AUTOSAR XML (schema 4-2-2)
package /STELLANTIS/EPT/ASWCs
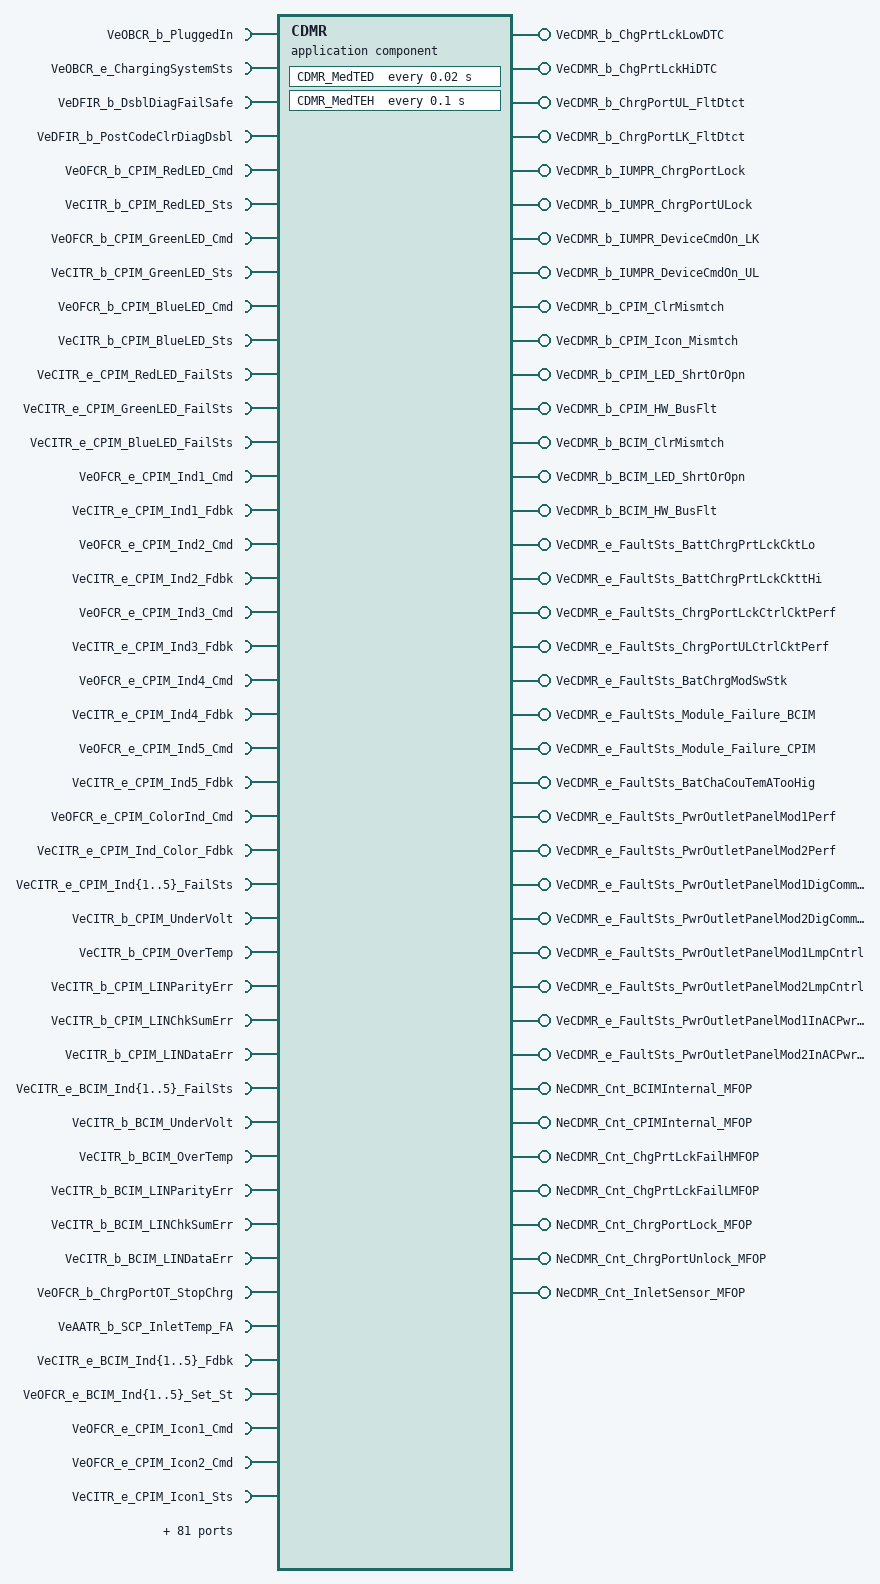
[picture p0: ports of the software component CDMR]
  application sw component type CDMR
    128 x require port:
      VeOBCR_b_PluggedIn: variation-point={short-label=vpVeOBCR_b_PluggedIn, sw-syscond=1}, nonqueued-receiver-com-spec{data-element=Value, init-value=0}, required-interface=VeOBCR_b_PluggedIn
      VeOBCR_e_ChargingSystemSts: variation-point={short-label=vpVeOBCR_e_ChargingSystemSts, sw-syscond=1}, nonqueued-receiver-com-spec{data-element=Value, init-value=CeOBCR_e_NotCharging}, required-interface=VeOBCR_e_ChargingSystemSts
      VeDFIR_b_DsblDiagFailSafe: variation-point={short-label=vpVeDFIR_b_DsblDiagFailSafe, sw-syscond=1}, nonqueued-receiver-com-spec{data-element=Value, init-value=0}, required-interface=VeDFIR_b_DsblDiagFailSafe
      VeDFIR_b_PostCodeClrDiagDsbl: variation-point={short-label=vpVeDFIR_b_PostCodeClrDiagDsbl, sw-syscond=1}, nonqueued-receiver-com-spec{data-element=Value, init-value=0}, required-interface=VeDFIR_b_PostCodeClrDiagDsbl
      VeOFCR_b_CPIM_RedLED_Cmd: variation-point={short-label=vpVeOFCR_b_CPIM_RedLED_Cmd, sw-syscond=1}, nonqueued-receiver-com-spec{data-element=Value, init-value=0}, required-interface=VeOFCR_b_CPIM_RedLED_Cmd
      VeCITR_b_CPIM_RedLED_Sts: variation-point={short-label=vpVeCITR_b_CPIM_RedLED_Sts, sw-syscond=1}, nonqueued-receiver-com-spec{data-element=Value, init-value=0}, required-interface=VeCITR_b_CPIM_RedLED_Sts
      VeOFCR_b_CPIM_GreenLED_Cmd: variation-point={short-label=vpVeOFCR_b_CPIM_GreenLED_Cmd, sw-syscond=1}, nonqueued-receiver-com-spec{data-element=Value, init-value=0}, required-interface=VeOFCR_b_CPIM_GreenLED_Cmd
      VeCITR_b_CPIM_GreenLED_Sts: variation-point={short-label=vpVeCITR_b_CPIM_GreenLED_Sts, sw-syscond=1}, nonqueued-receiver-com-spec{data-element=Value, init-value=0}, required-interface=VeCITR_b_CPIM_GreenLED_Sts
      VeOFCR_b_CPIM_BlueLED_Cmd: variation-point={short-label=vpVeOFCR_b_CPIM_BlueLED_Cmd, sw-syscond=1}, nonqueued-receiver-com-spec{data-element=Value, init-value=0}, required-interface=VeOFCR_b_CPIM_BlueLED_Cmd
      VeCITR_b_CPIM_BlueLED_Sts: variation-point={short-label=vpVeCITR_b_CPIM_BlueLED_Sts, sw-syscond=1}, nonqueued-receiver-com-spec{data-element=Value, init-value=0}, required-interface=VeCITR_b_CPIM_BlueLED_Sts
      VeCITR_e_CPIM_RedLED_FailSts: variation-point={short-label=vpVeCITR_e_CPIM_RedLED_FailSts, sw-syscond=1}, nonqueued-receiver-com-spec{data-element=Value, init-value=CeCITR_e_CPIM_LEDNormal}, required-interface=VeCITR_e_CPIM_RedLED_FailSts
      VeCITR_e_CPIM_GreenLED_FailSts: variation-point={short-label=vpVeCITR_e_CPIM_GreenLED_FailSts, sw-syscond=1}, nonqueued-receiver-com-spec{data-element=Value, init-value=CeCITR_e_CPIM_LEDNormal}, required-interface=VeCITR_e_CPIM_GreenLED_FailSts
      VeCITR_e_CPIM_BlueLED_FailSts: variation-point={short-label=vpVeCITR_e_CPIM_BlueLED_FailSts, sw-syscond=1}, nonqueued-receiver-com-spec{data-element=Value, init-value=CeCITR_e_CPIM_LEDNormal}, required-interface=VeCITR_e_CPIM_BlueLED_FailSts
      VeOFCR_e_CPIM_Ind1_Cmd: variation-point={short-label=vpVeOFCR_e_CPIM_Ind1_Cmd, sw-syscond=1}, nonqueued-receiver-com-spec{data-element=Value, init-value=CeCITR_e_CPIM_Ind_Off}, required-interface=VeOFCR_e_CPIM_Ind1_Cmd
      VeCITR_e_CPIM_Ind1_Fdbk: variation-point={short-label=vpVeCITR_e_CPIM_Ind1_Fdbk, sw-syscond=1}, nonqueued-receiver-com-spec{data-element=Value, init-value=CeCITR_e_CPIM_Ind_Off}, required-interface=VeCITR_e_CPIM_Ind1_Fdbk
      VeOFCR_e_CPIM_Ind2_Cmd: variation-point={short-label=vpVeOFCR_e_CPIM_Ind2_Cmd, sw-syscond=1}, nonqueued-receiver-com-spec{data-element=Value, init-value=CeCITR_e_CPIM_Ind_Off}, required-interface=VeOFCR_e_CPIM_Ind2_Cmd
      VeCITR_e_CPIM_Ind2_Fdbk: variation-point={short-label=vpVeCITR_e_CPIM_Ind2_Fdbk, sw-syscond=1}, nonqueued-receiver-com-spec{data-element=Value, init-value=CeCITR_e_CPIM_Ind_Off}, required-interface=VeCITR_e_CPIM_Ind2_Fdbk
      VeOFCR_e_CPIM_Ind3_Cmd: variation-point={short-label=vpVeOFCR_e_CPIM_Ind3_Cmd, sw-syscond=1}, nonqueued-receiver-com-spec{data-element=Value, init-value=CeCITR_e_CPIM_Ind_Off}, required-interface=VeOFCR_e_CPIM_Ind3_Cmd
      VeCITR_e_CPIM_Ind3_Fdbk: variation-point={short-label=vpVeCITR_e_CPIM_Ind3_Fdbk, sw-syscond=1}, nonqueued-receiver-com-spec{data-element=Value, init-value=CeCITR_e_CPIM_Ind_Off}, required-interface=VeCITR_e_CPIM_Ind3_Fdbk
      VeOFCR_e_CPIM_Ind4_Cmd: variation-point={short-label=vpVeOFCR_e_CPIM_Ind4_Cmd, sw-syscond=1}, nonqueued-receiver-com-spec{data-element=Value, init-value=CeCITR_e_CPIM_Ind_Off}, required-interface=VeOFCR_e_CPIM_Ind4_Cmd
      VeCITR_e_CPIM_Ind4_Fdbk: variation-point={short-label=vpVeCITR_e_CPIM_Ind4_Fdbk, sw-syscond=1}, nonqueued-receiver-com-spec{data-element=Value, init-value=CeCITR_e_CPIM_Ind_Off}, required-interface=VeCITR_e_CPIM_Ind4_Fdbk
      VeOFCR_e_CPIM_Ind5_Cmd: variation-point={short-label=vpVeOFCR_e_CPIM_Ind5_Cmd, sw-syscond=1}, nonqueued-receiver-com-spec{data-element=Value, init-value=CeCITR_e_CPIM_Ind_Off}, required-interface=VeOFCR_e_CPIM_Ind5_Cmd
      VeCITR_e_CPIM_Ind5_Fdbk: variation-point={short-label=vpVeCITR_e_CPIM_Ind5_Fdbk, sw-syscond=1}, nonqueued-receiver-com-spec{data-element=Value, init-value=CeCITR_e_CPIM_Ind_Off}, required-interface=VeCITR_e_CPIM_Ind5_Fdbk
      VeOFCR_e_CPIM_ColorInd_Cmd: variation-point={short-label=vpVeOFCR_e_CPIM_ColorInd_Cmd, sw-syscond=1}, nonqueued-receiver-com-spec{data-element=Value, init-value=CeCITR_e_CPIM_NoColor}, required-interface=VeOFCR_e_CPIM_ColorInd_Cmd
      VeCITR_e_CPIM_Ind_Color_Fdbk: variation-point={short-label=vpVeCITR_e_CPIM_Ind_Color_Fdbk, sw-syscond=1}, nonqueued-receiver-com-spec{data-element=Value, init-value=CeCITR_e_CPIM_NoColor}, required-interface=VeCITR_e_CPIM_Ind_Color_Fdbk
      VeCITR_e_CPIM_Ind{1..5}_FailSts: variation-point={short-label=vpVeCITR_e_CPIM_Ind{1..5}_FailSts, sw-syscond=1}, nonqueued-receiver-com-spec{data-element=Value, init-value=CeCITR_e_CPIM_LEDNormal}, required-interface=VeCITR_e_CPIM_Ind{1..5}_FailSts
      VeCITR_b_CPIM_UnderVolt: variation-point={short-label=vpVeCITR_b_CPIM_UnderVolt, sw-syscond=1}, nonqueued-receiver-com-spec{data-element=Value, init-value=0}, required-interface=VeCITR_b_CPIM_UnderVolt
      VeCITR_b_CPIM_OverTemp: variation-point={short-label=vpVeCITR_b_CPIM_OverTemp, sw-syscond=1}, nonqueued-receiver-com-spec{data-element=Value, init-value=0}, required-interface=VeCITR_b_CPIM_OverTemp
      VeCITR_b_CPIM_LINParityErr: variation-point={short-label=vpVeCITR_b_CPIM_LINParityErr, sw-syscond=1}, nonqueued-receiver-com-spec{data-element=Value, init-value=0}, required-interface=VeCITR_b_CPIM_LINParityErr
      VeCITR_b_CPIM_LINChkSumErr: variation-point={short-label=vpVeCITR_b_CPIM_LINChkSumErr, sw-syscond=1}, nonqueued-receiver-com-spec{data-element=Value, init-value=0}, required-interface=VeCITR_b_CPIM_LINChkSumErr
      VeCITR_b_CPIM_LINDataErr: variation-point={short-label=vpVeCITR_b_CPIM_LINDataErr, sw-syscond=1}, nonqueued-receiver-com-spec{data-element=Value, init-value=0}, required-interface=VeCITR_b_CPIM_LINDataErr
      VeCITR_e_BCIM_Ind{1..5}_FailSts: variation-point={short-label=vpVeCITR_e_BCIM_Ind{1..5}_FailSts, sw-syscond=1}, nonqueued-receiver-com-spec{data-element=Value, init-value=CeCITR_e_BCIM_LEDNormal}, required-interface=VeCITR_e_BCIM_Ind{1..5}_FailSts
      VeCITR_b_BCIM_UnderVolt: variation-point={short-label=vpVeCITR_b_BCIM_UnderVolt, sw-syscond=1}, nonqueued-receiver-com-spec{data-element=Value, init-value=0}, required-interface=VeCITR_b_BCIM_UnderVolt
      VeCITR_b_BCIM_OverTemp: variation-point={short-label=vpVeCITR_b_BCIM_OverTemp, sw-syscond=1}, nonqueued-receiver-com-spec{data-element=Value, init-value=0}, required-interface=VeCITR_b_BCIM_OverTemp
      VeCITR_b_BCIM_LINParityErr: variation-point={short-label=vpVeCITR_b_BCIM_LINParityErr, sw-syscond=1}, nonqueued-receiver-com-spec{data-element=Value, init-value=0}, required-interface=VeCITR_b_BCIM_LINParityErr
      VeCITR_b_BCIM_LINChkSumErr: variation-point={short-label=vpVeCITR_b_BCIM_LINChkSumErr, sw-syscond=1}, nonqueued-receiver-com-spec{data-element=Value, init-value=0}, required-interface=VeCITR_b_BCIM_LINChkSumErr
      VeCITR_b_BCIM_LINDataErr: variation-point={short-label=vpVeCITR_b_BCIM_LINDataErr, sw-syscond=1}, nonqueued-receiver-com-spec{data-element=Value, init-value=0}, required-interface=VeCITR_b_BCIM_LINDataErr
      VeOFCR_b_ChrgPortOT_StopChrg: variation-point={short-label=vpVeOFCR_b_ChrgPortOT_StopChrg, sw-syscond=1}, nonqueued-receiver-com-spec{data-element=Value, init-value=0}, required-interface=VeOFCR_b_ChrgPortOT_StopChrg
      VeAATR_b_SCP_InletTemp_FA: variation-point={short-label=vpVeAATR_b_SCP_InletTemp_FA, sw-syscond=1}, nonqueued-receiver-com-spec{data-element=Value, init-value=0}, required-interface=VeAATR_b_SCP_InletTemp_FA
      VeCITR_e_BCIM_Ind{1..5}_Fdbk: variation-point={short-label=vpVeCITR_e_BCIM_Ind{1..5}_Fdbk, sw-syscond=1}, nonqueued-receiver-com-spec{data-element=Value, init-value=CeCITR_e_BCIM_Ind_Off}, required-interface=VeCITR_e_BCIM_Ind{1..5}_Fdbk
      VeOFCR_e_BCIM_Ind{1..5}_Set_St: variation-point={short-label=vpVeOFCR_e_BCIM_Ind{1..5}_Set_St, sw-syscond=1}, nonqueued-receiver-com-spec{data-element=Value, init-value=CeCITR_e_BCIM_Ind_Off}, required-interface=VeOFCR_e_BCIM_Ind{1..5}_Set_St
      VeOFCR_e_CPIM_Icon1_Cmd: variation-point={short-label=vpVeOFCR_e_CPIM_Icon1_Cmd, sw-syscond=1}, nonqueued-receiver-com-spec{data-element=Value, init-value=CeCITR_e_CPIM_Icon_OFF}, required-interface=VeOFCR_e_CPIM_Icon1_Cmd
      VeOFCR_e_CPIM_Icon2_Cmd: variation-point={short-label=vpVeOFCR_e_CPIM_Icon2_Cmd, sw-syscond=1}, nonqueued-receiver-com-spec{data-element=Value, init-value=CeCITR_e_CPIM_Icon_OFF}, required-interface=VeOFCR_e_CPIM_Icon2_Cmd
      VeCITR_e_CPIM_Icon1_Sts: variation-point={short-label=vpVeCITR_e_CPIM_Icon1_Sts, sw-syscond=1}, nonqueued-receiver-com-spec{data-element=Value, init-value=CeCITR_e_CPIM_Icon_OFF}, required-interface=VeCITR_e_CPIM_Icon1_Sts
      VeCITR_e_CPIM_Icon2_Sts: variation-point={short-label=vpVeCITR_e_CPIM_Icon2_Sts, sw-syscond=1}, nonqueued-receiver-com-spec{data-element=Value, init-value=CeCITR_e_CPIM_Icon_OFF}, required-interface=VeCITR_e_CPIM_Icon2_Sts
      VeOBCR_b_ChrgSysFault: variation-point={short-label=vpVeOBCR_b_ChrgSysFault, sw-syscond=1}, nonqueued-receiver-com-spec{data-element=Value, init-value=0}, required-interface=VeOBCR_b_ChrgSysFault
      VeCITR_b_ChrgPortButton_Sts: variation-point={short-label=vpVeCITR_b_ChrgPortButton_Sts, sw-syscond=1}, nonqueued-receiver-com-spec{data-element=Value, init-value=0}, required-interface=VeCITR_b_ChrgPortButton_Sts
      VeSCPR_b_ButtonActive_Door: variation-point={short-label=vpVeSCPR_b_ButtonActive_Door, sw-syscond=1}, nonqueued-receiver-com-spec{data-element=Value, init-value=0}, required-interface=VeSCPR_b_ButtonActive_Door
      VeOBCR_e_ChrgPort_Req: variation-point={short-label=vpVeOBCR_e_ChrgPort_Req, sw-syscond=1}, nonqueued-receiver-com-spec{data-element=Value, init-value=CeOBCR_e_PortNoRequest}, required-interface=VeOBCR_e_ChrgPort_Req
      VeCITR_b_PortLockBCM_Cmd: variation-point={short-label=vpVeCITR_b_PortLockBCM_Cmd, sw-syscond=1}, nonqueued-receiver-com-spec{data-element=Value, init-value=0}, required-interface=VeCITR_b_PortLockBCM_Cmd
      VeCITR_b_ChrgPortLockSts: variation-point={short-label=vpVeCITR_b_ChrgPortLockSts, sw-syscond=1}, nonqueued-receiver-com-spec{data-element=Value, init-value=0}, required-interface=VeCITR_b_ChrgPortLockSts
      VeCANR_b_CBCLossComm_InKeyOff: variation-point={short-label=vpVeCANR_b_CBCLossComm_InKeyOff, sw-syscond=1}, nonqueued-receiver-com-spec{data-element=VeCANR_b_CBCLossComm_InKeyOff, init-value=0}, required-interface=VeCANR_b_CBCLossComm_InKeyOff
      VeCITR_e_ChrgPortLock_StsB: variation-point={short-label=vpVeCITR_e_ChrgPortLock_StsB, sw-syscond=1}, nonqueued-receiver-com-spec{data-element=Value, init-value=CeOBCR_e_DefaultLock_Sts}, required-interface=VeCITR_e_ChrgPortLock_StsB
      VeCITR_b_ChrgPortLock_StsB_FA: variation-point={short-label=vpVeCITR_b_ChrgPortLock_StsB_FA, sw-syscond=1}, nonqueued-receiver-com-spec{data-element=Value, init-value=0}, required-interface=VeCITR_b_ChrgPortLock_StsB_FA
      VeCITR_b_ChrgPortLock_StsC: variation-point={short-label=vpVeCITR_b_ChrgPortLock_StsC, sw-syscond=1}, nonqueued-receiver-com-spec{data-element=Value, init-value=0}, required-interface=VeCITR_b_ChrgPortLock_StsC
      VeCITR_b_ChrgPortLock_StsC_FA: variation-point={short-label=vpVeCITR_b_ChrgPortLock_StsC_FA, sw-syscond=1}, nonqueued-receiver-com-spec{data-element=Value, init-value=0}, required-interface=VeCITR_b_ChrgPortLock_StsC_FA
      VeCITR_b_HBridge_ChrgPortLck_Cal: variation-point={short-label=vpVeCITR_b_HBridge_ChrgPortLck_Cal, sw-syscond=1}, nonqueued-receiver-com-spec{data-element=Value, init-value=0}, required-interface=VeCITR_b_HBridge_ChrgPortLck_Cal
      VeCITR_d_ChrgPortHbridgeFlt: variation-point={short-label=vpVeCITR_d_ChrgPortHbridgeFlt, sw-syscond=1}, nonqueued-receiver-com-spec{data-element=Value, init-value=0}, required-interface=VeCITR_d_ChrgPortHbridgeFlt
      VeCITR_e_CPIM_ChrgPortLock_FailSts: variation-point={short-label=vpVeCITR_e_CPIM_ChrgPortLock_FailSts, sw-syscond=1}, nonqueued-receiver-com-spec{data-element=Value, init-value=CeCITR_e_CPIMLock_Nofailure}, required-interface=VeCITR_e_CPIM_ChrgPortLock_FailSts
      VeDFIR_b_IsDiagGlobalConditionsValid: variation-point={short-label=vpVeDFIR_b_IsDiagGlobalConditionsValid, sw-syscond=1}, nonqueued-receiver-com-spec{data-element=Value, init-value=0}, required-interface=VeDFIR_b_IsDiagGlobalConditionsValid
      VeOFCR_e_BCIM_ColorInd_Cmd: variation-point={short-label=vpVeOFCR_e_BCIM_ColorInd_Cmd, sw-syscond=1}, nonqueued-receiver-com-spec{data-element=Value, init-value=CeCITR_e_BCIM_NoColor}, required-interface=VeOFCR_e_BCIM_ColorInd_Cmd
      VeCITR_e_BCIM_Ind_Color_Fdbk: variation-point={short-label=vpVeCITR_e_BCIM_Ind_Color_Fdbk, sw-syscond=1}, nonqueued-receiver-com-spec{data-element=Value, init-value=CeCITR_e_BCIM_NoColor}, required-interface=VeCITR_e_BCIM_Ind_Color_Fdbk
      VeCITR_b_CPIM_Icon1_FailSts: variation-point={short-label=vpVeCITR_b_CPIM_Icon1_FailSts, sw-syscond=1}, nonqueued-receiver-com-spec{data-element=Value, init-value=0}, required-interface=VeCITR_b_CPIM_Icon1_FailSts
      VeCITR_b_CPIM_Icon2_FailSts: variation-point={short-label=vpVeCITR_b_CPIM_Icon2_FailSts, sw-syscond=1}, nonqueued-receiver-com-spec{data-element=Value, init-value=0}, required-interface=VeCITR_b_CPIM_Icon2_FailSts
      VeDMAB_y_StatusByte_HiSpdCANCommBus: variation-point={short-label=vpVeDMAB_y_StatusByte_HiSpdCANCommBus, sw-syscond=1}, nonqueued-receiver-com-spec{data-element=Value, init-value=0}, required-interface=VeDMAB_y_StatusByte_HiSpdCANCommBus
      VeDMAB_y_StatusByte_LostCommBCM: variation-point={short-label=vpVeDMAB_y_StatusByte_LostCommBCM, sw-syscond=1}, nonqueued-receiver-com-spec{data-element=Value, init-value=0}, required-interface=VeDMAB_y_StatusByte_LostCommBCM
      VeDMAB_y_StatusByte_LIN{1..3}_BusOff: variation-point={short-label=vpVeDMAB_y_StatusByte_LIN{1..3}_BusOff, sw-syscond=1}, nonqueued-receiver-com-spec{data-element=Value, init-value=0}, required-interface=VeDMAB_y_StatusByte_LIN{1..3}_BusOff
      VeDMAB_y_StatusByte_LostCommCPIM: variation-point={short-label=vpVeDMAB_y_StatusByte_LostCommCPIM, sw-syscond=1}, nonqueued-receiver-com-spec{data-element=Value, init-value=0}, required-interface=VeDMAB_y_StatusByte_LostCommCPIM
      VeDMAB_y_StatusByte_LostCommBCIM: variation-point={short-label=vpVeDMAB_y_StatusByte_LostCommBCIM, sw-syscond=1}, nonqueued-receiver-com-spec{data-element=Value, init-value=0}, required-interface=VeDMAB_y_StatusByte_LostCommBCIM
      VeDMAB_y_StatusByte_BatChrgModSwStk: variation-point={short-label=vpVeDMAB_y_StatusByte_BatChrgModSwStk, sw-syscond=1}, nonqueued-receiver-com-spec{data-element=Value, init-value=0}, required-interface=VeDMAB_y_StatusByte_BatChrgModSwStk
      VeDMAB_y_StatusByte_Module_Failure_CPIM: variation-point={short-label=vpVeDMAB_y_StatusByte_Module_Failure_CPIM, sw-syscond=1}, nonqueued-receiver-com-spec{data-element=Value, init-value=0}, required-interface=VeDMAB_y_StatusByte_Module_Failure_CPIM
      VeDMAB_y_StatusByte_Module_Failure_BCIM: variation-point={short-label=vpVeDMAB_y_StatusByte_Module_Failure_BCIM, sw-syscond=1}, nonqueued-receiver-com-spec{data-element=Value, init-value=0}, required-interface=VeDMAB_y_StatusByte_Module_Failure_BCIM
      VeDMAB_y_StatusByte_BatChaCouTemATooHig: variation-point={short-label=vpVeDMAB_y_StatusByte_BatChaCouTemATooHig, sw-syscond=1}, nonqueued-receiver-com-spec{data-element=Value, init-value=0}, required-interface=VeDMAB_y_StatusByte_BatChaCouTemATooHig
      VeDMAB_y_StatusByte_ChrgPortLckCtrlCktPerf: variation-point={short-label=vpVeDMAB_y_StatusByte_ChrgPortLckCtrlCktPerf, sw-syscond=1}, nonqueued-receiver-com-spec{data-element=Value, init-value=0}, required-interface=VeDMAB_y_StatusByte_ChrgPortLckCtrlCktPerf
      VeDMAB_y_StatusByte_ChrgPortULCtrlCktPerf: variation-point={short-label=vpVeDMAB_y_StatusByte_ChrgPortULCtrlCktPerf, sw-syscond=1}, nonqueued-receiver-com-spec{data-element=Value, init-value=0}, required-interface=VeDMAB_y_StatusByte_ChrgPortULCtrlCktPerf
      VeDMAB_y_StatusByte_BattChrgPrtLckCkttHi: variation-point={short-label=vpVeDMAB_y_StatusByte_BattChrgPrtLckCkttHi, sw-syscond=1}, nonqueued-receiver-com-spec{data-element=Value, init-value=0}, required-interface=VeDMAB_y_StatusByte_BattChrgPrtLckCkttHi
      VeDMAB_y_StatusByte_BattChrgPrtLckCktLo: variation-point={short-label=vpVeDMAB_y_StatusByte_BattChrgPrtLckCktLo, sw-syscond=1}, nonqueued-receiver-com-spec{data-element=Value, init-value=0}, required-interface=VeDMAB_y_StatusByte_BattChrgPrtLckCktLo
      VeVTLR_e_TrunkSts: variation-point={short-label=vpVeVTLR_e_TrunkSts, sw-syscond=1}, nonqueued-receiver-com-spec{data-element=Value, init-value=CeVTLR_e_Inactive}, required-interface=VeVTLR_e_TrunkSts
      VeDMAB_y_StatusByte_PwrOutletPanelMod1Perf: variation-point={short-label=vpVeDMAB_y_StatusByte_PwrOutletPanelMod1Perf, sw-syscond=1}, nonqueued-receiver-com-spec{data-element=Value, init-value=0}, required-interface=VeDMAB_y_StatusByte_PwrOutletPanelMod1Perf
      VeCITR_b_PP2ButtonSts: variation-point={short-label=vpVeCITR_b_PP2ButtonSts, sw-syscond=1}, nonqueued-receiver-com-spec{data-element=Value, init-value=0}, required-interface=VeCITR_b_PP2ButtonSts
      VePMDB_b_PwrPanSwStatus: variation-point={short-label=vpVePMDB_b_PwrPanSwStatus, sw-syscond=1}, nonqueued-receiver-com-spec{data-element=Value, init-value=0}, required-interface=VePMDB_b_PwrPanSwStatus
      VeDMAB_y_StatusByte_PwrOutletPanelMod1DigCommBus: variation-point={short-label=vpVeDMAB_y_StatusByte_PwrOutletPanelMod1DigCommBus, sw-syscond=1}, nonqueued-receiver-com-spec{data-element=Value, init-value=0}, required-interface=VeDMAB_y_StatusByte_PwrOutletPanelMod1DigCommBus
      VePMTR_e_ThrmlDevEnbl: variation-point={short-label=vpVePMTR_e_ThrmlDevEnbl, sw-syscond=1}, nonqueued-receiver-com-spec{data-element=Value, init-value=CePMTR_e_DISBL_All_Thrml}, required-interface=VePMTR_e_ThrmlDevEnbl
      VeCITR_e_PP_LED_A_Feedback: variation-point={short-label=vpVeCITR_e_PP_LED_A_Feedback, sw-syscond=1}, nonqueued-receiver-com-spec{data-element=Value, init-value=CeCITR_e_CPIM_Ind_Off}, required-interface=VeCITR_e_PP_LED_A_Feedback
      VeCITR_e_PP_LED_B_Feedback: variation-point={short-label=vpVeCITR_e_PP_LED_B_Feedback, sw-syscond=1}, nonqueued-receiver-com-spec{data-element=Value, init-value=CeCITR_e_CPIM_Ind_Off}, required-interface=VeCITR_e_PP_LED_B_Feedback
      VeCITR_e_PP_LED_A_FailStatus: variation-point={short-label=vpVeCITR_e_PP_LED_A_FailStatus, sw-syscond=1}, nonqueued-receiver-com-spec{data-element=Value, init-value=CeCITR_e_CPIM_LEDNormal}, required-interface=VeCITR_e_PP_LED_A_FailStatus
      VeCITR_e_PP_LED_B_FailStatus: variation-point={short-label=vpVeCITR_e_PP_LED_B_FailStatus, sw-syscond=1}, nonqueued-receiver-com-spec{data-element=Value, init-value=CeCITR_e_CPIM_LEDNormal}, required-interface=VeCITR_e_PP_LED_B_FailStatus
      VeVTLR_e_PP1_LEDA_Cmd: variation-point={short-label=vpVeVTLR_e_PP1_LEDA_Cmd, sw-syscond=1}, nonqueued-receiver-com-spec{data-element=Value, init-value=CeVTLR_e_Led_Off}, required-interface=VeVTLR_e_PP1_LEDA_Cmd
      VeVTLR_e_PP1_LEDB_Cmd: variation-point={short-label=vpVeVTLR_e_PP1_LEDB_Cmd, sw-syscond=1}, nonqueued-receiver-com-spec{data-element=Value, init-value=CeVTLR_e_Led_Off}, required-interface=VeVTLR_e_PP1_LEDB_Cmd
      VeDMAB_y_StatusByte_PwrOutletPanelMod1LmpCntrl: variation-point={short-label=vpVeDMAB_y_StatusByte_PwrOutletPanelMod1LmpCntrl, sw-syscond=1}, nonqueued-receiver-com-spec{data-element=Value, init-value=0}, required-interface=VeDMAB_y_StatusByte_PwrOutletPanelMod1LmpCntrl
      VeIDCR_U_ACOutVoltage1: variation-point={short-label=vpVeIDCR_U_ACOutVoltage1, sw-syscond=1}, nonqueued-receiver-com-spec{data-element=Value, init-value=0}, required-interface=VeIDCR_U_ACOutVoltage1
      VeCITR_b_PPACPresentSens1: variation-point={short-label=vpVeCITR_b_PPACPresentSens1, sw-syscond=1}, nonqueued-receiver-com-spec{data-element=Value, init-value=0}, required-interface=VeCITR_b_PPACPresentSens1
      VeDMAB_y_StatusByte_PwrOutletPanelMod1InACPwrCktPerf: variation-point={short-label=vpVeDMAB_y_StatusByte_PwrOutletPanelMod1InACPwrCktPerf, sw-syscond=1}, nonqueued-receiver-com-spec{data-element=Value, init-value=0}, required-interface=VeDMAB_y_StatusByte_PwrOutletPanelMod1InACPwrCktPerf
      VeDMAB_y_StatusByte_PwrOutletPanelMod2Perf: variation-point={short-label=vpVeDMAB_y_StatusByte_PwrOutletPanelMod2Perf, sw-syscond=1}, nonqueued-receiver-com-spec{data-element=Value, init-value=0}, required-interface=VeDMAB_y_StatusByte_PwrOutletPanelMod2Perf
      VeCITR_b_PPButtonSts: variation-point={short-label=vpVeCITR_b_PPButtonSts, sw-syscond=1}, nonqueued-receiver-com-spec{data-element=Value, init-value=0}, required-interface=VeCITR_b_PPButtonSts
      VeDMAB_y_StatusByte_PwrOutletPanelMod2DigCommBus: variation-point={short-label=vpVeDMAB_y_StatusByte_PwrOutletPanelMod2DigCommBus, sw-syscond=1}, nonqueued-receiver-com-spec{data-element=Value, init-value=0}, required-interface=VeDMAB_y_StatusByte_PwrOutletPanelMod2DigCommBus
      VeCITR_e_PP2_LED_A_Feedback: variation-point={short-label=vpVeCITR_e_PP2_LED_A_Feedback, sw-syscond=1}, nonqueued-receiver-com-spec{data-element=Value, init-value=CeCITR_e_CPIM_Ind_Off}, required-interface=VeCITR_e_PP2_LED_A_Feedback
      VeCITR_e_PP2_LED_B_Feedback: variation-point={short-label=vpVeCITR_e_PP2_LED_B_Feedback, sw-syscond=1}, nonqueued-receiver-com-spec{data-element=Value, init-value=CeCITR_e_CPIM_Ind_Off}, required-interface=VeCITR_e_PP2_LED_B_Feedback
      VeCITR_e_PP2_LED_A_FailStatus: variation-point={short-label=vpVeCITR_e_PP2_LED_A_FailStatus, sw-syscond=1}, nonqueued-receiver-com-spec{data-element=Value, init-value=CeCITR_e_CPIM_LEDNormal}, required-interface=VeCITR_e_PP2_LED_A_FailStatus
      VeCITR_e_PP2_LED_B_FailStatus: variation-point={short-label=vpVeCITR_e_PP2_LED_B_FailStatus, sw-syscond=1}, nonqueued-receiver-com-spec{data-element=Value, init-value=CeCITR_e_CPIM_LEDNormal}, required-interface=VeCITR_e_PP2_LED_B_FailStatus
      VeVTLR_e_PP2_LEDA_Cmd: variation-point={short-label=vpVeVTLR_e_PP2_LEDA_Cmd, sw-syscond=1}, nonqueued-receiver-com-spec{data-element=Value, init-value=CeVTLR_e_Led_Off}, required-interface=VeVTLR_e_PP2_LEDA_Cmd
      VeVTLR_e_PP2_LEDB_Cmd: variation-point={short-label=vpVeVTLR_e_PP2_LEDB_Cmd, sw-syscond=1}, nonqueued-receiver-com-spec{data-element=Value, init-value=CeVTLR_e_Led_Off}, required-interface=VeVTLR_e_PP2_LEDB_Cmd
      VeDMAB_y_StatusByte_PwrOutletPanelMod2LmpCntrl: variation-point={short-label=vpVeDMAB_y_StatusByte_PwrOutletPanelMod2LmpCntrl, sw-syscond=1}, nonqueued-receiver-com-spec{data-element=Value, init-value=0}, required-interface=VeDMAB_y_StatusByte_PwrOutletPanelMod2LmpCntrl
      VeCITR_b_PP2ACPresentSens1: variation-point={short-label=vpVeCITR_b_PP2ACPresentSens1, sw-syscond=1}, nonqueued-receiver-com-spec{data-element=Value, init-value=0}, required-interface=VeCITR_b_PP2ACPresentSens1
      VeDMAB_y_StatusByte_PwrOutletPanelMod2InACPwrCktPerf: variation-point={short-label=vpVeDMAB_y_StatusByte_PwrOutletPanelMod2InACPwrCktPerf, sw-syscond=1}, nonqueued-receiver-com-spec{data-element=Value, init-value=0}, required-interface=VeDMAB_y_StatusByte_PwrOutletPanelMod2InACPwrCktPerf
      VeCITR_I_PP2CurrentDrawSens1: variation-point={short-label=vpVeCITR_I_PP2CurrentDrawSens1, sw-syscond=1}, nonqueued-receiver-com-spec{data-element=Value, init-value=0}, required-interface=VeCITR_I_PP2CurrentDrawSens1
      VeVTLR_e_FrunkSts: variation-point={short-label=vpVeVTLR_e_FrunkSts, sw-syscond=1}, nonqueued-receiver-com-spec{data-element=Value, init-value=CeVTLR_e_Inactive_Frunk}, required-interface=VeVTLR_e_FrunkSts
      VeVTLR_b_ACSw_Cmd: variation-point={short-label=vpVeVTLR_b_ACSw_Cmd, sw-syscond=1}, nonqueued-receiver-com-spec{data-element=Value, init-value=0}, required-interface=VeVTLR_b_ACSw_Cmd
      VeCITR_I_PPCurrentDrawSens1: variation-point={short-label=vpVeCITR_I_PPCurrentDrawSens1, sw-syscond=1}, nonqueued-receiver-com-spec{data-element=Value, init-value=0}, required-interface=VeCITR_I_PPCurrentDrawSens1
      VeIDCR_I_ACOutCurrent1: variation-point={short-label=vpVeIDCR_I_ACOutCurrent1, sw-syscond=1}, nonqueued-receiver-com-spec{data-element=Value, init-value=0}, required-interface=VeIDCR_I_ACOutCurrent1
    31 x provide port:
      VeCDMR_b_ChgPrtLckLowDTC: nonqueued-sender-com-spec{data-element=Value, init-value=0}, provided-interface=VeCDMR_b_ChgPrtLckLowDTC
      VeCDMR_b_ChgPrtLckHiDTC: nonqueued-sender-com-spec{data-element=Value, init-value=0}, provided-interface=VeCDMR_b_ChgPrtLckHiDTC
      VeCDMR_b_ChrgPortUL_FltDtct: nonqueued-sender-com-spec{data-element=Value, init-value=0}, provided-interface=VeCDMR_b_ChrgPortUL_FltDtct
      VeCDMR_b_ChrgPortLK_FltDtct: nonqueued-sender-com-spec{data-element=Value, init-value=0}, provided-interface=VeCDMR_b_ChrgPortLK_FltDtct
      VeCDMR_b_IUMPR_ChrgPortLock: nonqueued-sender-com-spec{data-element=Value, init-value=0}, provided-interface=VeCDMR_b_IUMPR_ChrgPortLock
      VeCDMR_b_IUMPR_ChrgPortULock: nonqueued-sender-com-spec{data-element=Value, init-value=0}, provided-interface=VeCDMR_b_IUMPR_ChrgPortULock
      VeCDMR_b_IUMPR_DeviceCmdOn_LK: nonqueued-sender-com-spec{data-element=Value, init-value=0}, provided-interface=VeCDMR_b_IUMPR_DeviceCmdOn_LK
      VeCDMR_b_IUMPR_DeviceCmdOn_UL: nonqueued-sender-com-spec{data-element=Value, init-value=0}, provided-interface=VeCDMR_b_IUMPR_DeviceCmdOn_UL
      VeCDMR_b_CPIM_ClrMismtch: nonqueued-sender-com-spec{data-element=Value, init-value=0}, provided-interface=VeCDMR_b_CPIM_ClrMismtch
      VeCDMR_b_CPIM_Icon_Mismtch: nonqueued-sender-com-spec{data-element=Value, init-value=0}, provided-interface=VeCDMR_b_CPIM_Icon_Mismtch
      VeCDMR_b_CPIM_LED_ShrtOrOpn: nonqueued-sender-com-spec{data-element=Value, init-value=0}, provided-interface=VeCDMR_b_CPIM_LED_ShrtOrOpn
      VeCDMR_b_CPIM_HW_BusFlt: nonqueued-sender-com-spec{data-element=Value, init-value=0}, provided-interface=VeCDMR_b_CPIM_HW_BusFlt
      VeCDMR_b_BCIM_ClrMismtch: nonqueued-sender-com-spec{data-element=Value, init-value=0}, provided-interface=VeCDMR_b_BCIM_ClrMismtch
      VeCDMR_b_BCIM_LED_ShrtOrOpn: nonqueued-sender-com-spec{data-element=Value, init-value=0}, provided-interface=VeCDMR_b_BCIM_LED_ShrtOrOpn
      VeCDMR_b_BCIM_HW_BusFlt: nonqueued-sender-com-spec{data-element=Value, init-value=0}, provided-interface=VeCDMR_b_BCIM_HW_BusFlt
      VeCDMR_e_FaultSts_BattChrgPrtLckCktLo: nonqueued-sender-com-spec{data-element=Value, init-value=CeDFIB_e_Init}, provided-interface=VeCDMR_e_FaultSts_BattChrgPrtLckCktLo
      VeCDMR_e_FaultSts_BattChrgPrtLckCkttHi: nonqueued-sender-com-spec{data-element=Value, init-value=CeDFIB_e_Init}, provided-interface=VeCDMR_e_FaultSts_BattChrgPrtLckCkttHi
      VeCDMR_e_FaultSts_ChrgPortLckCtrlCktPerf: nonqueued-sender-com-spec{data-element=Value, init-value=CeDFIB_e_Init}, provided-interface=VeCDMR_e_FaultSts_ChrgPortLckCtrlCktPerf
      VeCDMR_e_FaultSts_ChrgPortULCtrlCktPerf: nonqueued-sender-com-spec{data-element=Value, init-value=CeDFIB_e_Init}, provided-interface=VeCDMR_e_FaultSts_ChrgPortULCtrlCktPerf
      VeCDMR_e_FaultSts_BatChrgModSwStk: nonqueued-sender-com-spec{data-element=Value, init-value=CeDFIB_e_Init}, provided-interface=VeCDMR_e_FaultSts_BatChrgModSwStk
      VeCDMR_e_FaultSts_Module_Failure_BCIM: nonqueued-sender-com-spec{data-element=Value, init-value=CeDFIB_e_Init}, provided-interface=VeCDMR_e_FaultSts_Module_Failure_BCIM
      VeCDMR_e_FaultSts_Module_Failure_CPIM: nonqueued-sender-com-spec{data-element=Value, init-value=CeDFIB_e_Init}, provided-interface=VeCDMR_e_FaultSts_Module_Failure_CPIM
      VeCDMR_e_FaultSts_BatChaCouTemATooHig: nonqueued-sender-com-spec{data-element=Value, init-value=CeDFIB_e_Init}, provided-interface=VeCDMR_e_FaultSts_BatChaCouTemATooHig
      VeCDMR_e_FaultSts_PwrOutletPanelMod1Perf: nonqueued-sender-com-spec{data-element=Value, init-value=CeDFIB_e_Init}, provided-interface=VeCDMR_e_FaultSts_PwrOutletPanelMod1Perf
      VeCDMR_e_FaultSts_PwrOutletPanelMod2Perf: nonqueued-sender-com-spec{data-element=Value, init-value=CeDFIB_e_Init}, provided-interface=VeCDMR_e_FaultSts_PwrOutletPanelMod2Perf
      VeCDMR_e_FaultSts_PwrOutletPanelMod1DigCommBus: nonqueued-sender-com-spec{data-element=Value, init-value=CeDFIB_e_Init}, provided-interface=VeCDMR_e_FaultSts_PwrOutletPanelMod1DigCommBus
      VeCDMR_e_FaultSts_PwrOutletPanelMod2DigCommBus: nonqueued-sender-com-spec{data-element=Value, init-value=CeDFIB_e_Init}, provided-interface=VeCDMR_e_FaultSts_PwrOutletPanelMod2DigCommBus
      VeCDMR_e_FaultSts_PwrOutletPanelMod1LmpCntrl: nonqueued-sender-com-spec{data-element=Value, init-value=CeDFIB_e_Init}, provided-interface=VeCDMR_e_FaultSts_PwrOutletPanelMod1LmpCntrl
      VeCDMR_e_FaultSts_PwrOutletPanelMod2LmpCntrl: nonqueued-sender-com-spec{data-element=Value, init-value=CeDFIB_e_Init}, provided-interface=VeCDMR_e_FaultSts_PwrOutletPanelMod2LmpCntrl
      VeCDMR_e_FaultSts_PwrOutletPanelMod1InACPwrCktPerf: nonqueued-sender-com-spec{data-element=Value, init-value=CeDFIB_e_Init}, provided-interface=VeCDMR_e_FaultSts_PwrOutletPanelMod1InACPwrCktPerf
      VeCDMR_e_FaultSts_PwrOutletPanelMod2InACPwrCktPerf: nonqueued-sender-com-spec{data-element=Value, init-value=CeDFIB_e_Init}, provided-interface=VeCDMR_e_FaultSts_PwrOutletPanelMod2InACPwrCktPerf
    15 x require port:
      NeCDMR_Cnt_BCIMInternal_MFOP_Rx: nv-require-com-spec{init-value=0, variable=NeCDMR_Cnt_BCIMInternal_MFOP}, required-interface=NeCDMR_Cnt_BCIMInternal_MFOP
      NeCDMR_Cnt_CPIMInternal_MFOP_Rx: nv-require-com-spec{init-value=0, variable=NeCDMR_Cnt_CPIMInternal_MFOP}, required-interface=NeCDMR_Cnt_CPIMInternal_MFOP
      NeCDMR_Cnt_ChgPrtLckFailHMFOP_Rx: nv-require-com-spec{init-value=0, variable=NeCDMR_Cnt_ChgPrtLckFailHMFOP}, required-interface=NeCDMR_Cnt_ChgPrtLckFailHMFOP
      NeCDMR_Cnt_ChgPrtLckFailLMFOP_Rx: nv-require-com-spec{init-value=0, variable=NeCDMR_Cnt_ChgPrtLckFailLMFOP}, required-interface=NeCDMR_Cnt_ChgPrtLckFailLMFOP
      NeCDMR_Cnt_ChrgPortLock_MFOP_Rx: nv-require-com-spec{init-value=0, variable=NeCDMR_Cnt_ChrgPortLock_MFOP}, required-interface=NeCDMR_Cnt_ChrgPortLock_MFOP
      NeCDMR_Cnt_ChrgPortUnlock_MFOP_Rx: nv-require-com-spec{init-value=0, variable=NeCDMR_Cnt_ChrgPortUnlock_MFOP}, required-interface=NeCDMR_Cnt_ChrgPortUnlock_MFOP
      NeCDMR_Cnt_InletSensor_MFOP_Rx: nv-require-com-spec{init-value=0, variable=NeCDMR_Cnt_InletSensor_MFOP}, required-interface=NeCDMR_Cnt_InletSensor_MFOP
      NeCDMR_Cnt_PwrOutletPanelMod1Perf_MFOP_Rx: nv-require-com-spec{init-value=0, variable=NeCDMR_Cnt_PwrOutletPanelMod1Perf_MFOP}, required-interface=NeCDMR_Cnt_PwrOutletPanelMod1Perf_MFOP
      NeCDMR_Cnt_DTCShortName6_MFOP_Rx: nv-require-com-spec{init-value=0, variable=NeCDMR_Cnt_DTCShortName6_MFOP}, required-interface=NeCDMR_Cnt_DTCShortName6_MFOP
      NeCDMR_Cnt_DTCShortName1_MFOP_Rx: nv-require-com-spec{init-value=0, variable=NeCDMR_Cnt_DTCShortName1_MFOP}, required-interface=NeCDMR_Cnt_DTCShortName1_MFOP
      NeCDMR_Cnt_PwrOutletPanelMod2DigCommBus_MFOP_Rx: nv-require-com-spec{init-value=0, variable=NeCDMR_Cnt_PwrOutletPanelMod2DigCommBus_MFOP}, required-interface=NeCDMR_Cnt_PwrOutletPanelMod2DigCommBus_MFOP
      NeCDMR_Cnt_PwrOutletPanelMod1LmpCntrl_MFOP_Rx: nv-require-com-spec{init-value=0, variable=NeCDMR_Cnt_PwrOutletPanelMod1LmpCntrl_MFOP}, required-interface=NeCDMR_Cnt_PwrOutletPanelMod1LmpCntrl_MFOP
      NeCDMR_Cnt_PwrOutletPanelMod2LmpCntrl_MFOP_Rx: nv-require-com-spec{init-value=0, variable=NeCDMR_Cnt_PwrOutletPanelMod2LmpCntrl_MFOP}, required-interface=NeCDMR_Cnt_PwrOutletPanelMod2LmpCntrl_MFOP
      NeCDMR_Cnt_PwrOutletPanelMod1InACPwrCktPerf_MFOP_Rx: nv-require-com-spec{init-value=0, variable=NeCDMR_Cnt_PwrOutletPanelMod1InACPwrCktPerf_MFOP}, required-interface=NeCDMR_Cnt_PwrOutletPanelMod1InACPwrCktPerf_MFOP
      NeCDMR_Cnt_PwrOutletPanelMod2InACPwrCktPerf_MFOP_Rx: nv-require-com-spec{init-value=0, variable=NeCDMR_Cnt_PwrOutletPanelMod2InACPwrCktPerf_MFOP}, required-interface=NeCDMR_Cnt_PwrOutletPanelMod2InACPwrCktPerf_MFOP
    7 x provide port:
      NeCDMR_Cnt_BCIMInternal_MFOP: nv-provide-com-spec{ram-block-init-value=0, variable=NeCDMR_Cnt_BCIMInternal_MFOP}, provided-interface=NeCDMR_Cnt_BCIMInternal_MFOP
      NeCDMR_Cnt_CPIMInternal_MFOP: nv-provide-com-spec{ram-block-init-value=0, variable=NeCDMR_Cnt_CPIMInternal_MFOP}, provided-interface=NeCDMR_Cnt_CPIMInternal_MFOP
      NeCDMR_Cnt_ChgPrtLckFailHMFOP: nv-provide-com-spec{ram-block-init-value=0, variable=NeCDMR_Cnt_ChgPrtLckFailHMFOP}, provided-interface=NeCDMR_Cnt_ChgPrtLckFailHMFOP
      NeCDMR_Cnt_ChgPrtLckFailLMFOP: nv-provide-com-spec{ram-block-init-value=0, variable=NeCDMR_Cnt_ChgPrtLckFailLMFOP}, provided-interface=NeCDMR_Cnt_ChgPrtLckFailLMFOP
      NeCDMR_Cnt_ChrgPortLock_MFOP: nv-provide-com-spec{ram-block-init-value=0, variable=NeCDMR_Cnt_ChrgPortLock_MFOP}, provided-interface=NeCDMR_Cnt_ChrgPortLock_MFOP
      NeCDMR_Cnt_ChrgPortUnlock_MFOP: nv-provide-com-spec{ram-block-init-value=0, variable=NeCDMR_Cnt_ChrgPortUnlock_MFOP}, provided-interface=NeCDMR_Cnt_ChrgPortUnlock_MFOP
      NeCDMR_Cnt_InletSensor_MFOP: nv-provide-com-spec{ram-block-init-value=0, variable=NeCDMR_Cnt_InletSensor_MFOP}, provided-interface=NeCDMR_Cnt_InletSensor_MFOP
    behavior IB_CDMR: data-type-mapping=msADTtoIDTMapping, handle-termination-and-restart=NO-SUPPORT
      timing event Event_MedTED: start-on-event=CDMR_MedTED, period=0.02
      timing event Event_MedTEH: start-on-event=CDMR_MedTEH, period=0.1
      init event Event_CDMR_ac_Init: start-on-event=CDMR_ac_Init
      init event Event_PwrOn: start-on-event=CDMR_PwrOn
      init event Event_PwrOff: start-on-event=CDMR_PwrOff
      explicit-inter-runnable-variables:
        16 x data, all with category=VALUE, sw-calibration-access=READ-ONLY:
          DsblDiagFailSafe_write_IRV: type=Boolean, init-value=0, variation-point={short-label=vpDsblDiagFailSafe_write_IRV, sw-syscond=1}
          PostCodeClrDiagDsbl_write_IRV: type=Boolean, init-value=0, variation-point={short-label=vpPostCodeClrDiagDsbl_write_IRV, sw-syscond=1}
          CPIMCommBusFaultStatus_write_IRV: type=Boolean, init-value=0, variation-point={short-label=vpCPIMCommBusFaultStatus_write_IRV, sw-syscond=1}
          CPIMLostCommFaultStatus_write_IRV: type=Boolean, init-value=0, variation-point={short-label=vpCPIMLostCommFaultStatus_write_IRV, sw-syscond=1}
          IsDiagGlobalConditionsValid_write_IRV: type=Boolean, init-value=0, variation-point={short-label=vpIsDiagGlobalConditionsValid_write_IRV, sw-syscond=1}
          PluggedIn_write_IRV: type=Boolean, init-value=0, variation-point={short-label=vpPluggedIn_write_IRV, sw-syscond=1}
          ChargingSystemSts_write_IRV: type=TeOBCR_e_ChargingSystemSts, init-value=CeOBCR_e_NotCharging, variation-point={short-label=vpChargingSystemSts_write_IRV, sw-syscond=1}
          BCIMCommBusFaultStatus_write_IRV: type=Boolean, init-value=0, variation-point={short-label=vpBCIMCommBusFaultStatus_write_IRV, sw-syscond=1}
          ChgPrtLckLowDTC_write_IRV: type=Boolean, init-value=0, variation-point={short-label=vpChgPrtLckLowDTC_write_IRV, sw-syscond=1}
          ChgPrtLckHiDTC_write_IRV: type=Boolean, init-value=0, variation-point={short-label=vpChgPrtLckHiDTC_write_IRV, sw-syscond=1}
          ChrgPortUL_FltDtct_write_IRV: type=Boolean, init-value=0, variation-point={short-label=vpChrgPortUL_FltDtct_write_IRV, sw-syscond=1}
          ChrgPortLK_FltDtct_write_IRV: type=Boolean, init-value=0, variation-point={short-label=vpChrgPortLK_FltDtct_write_IRV, sw-syscond=1}
          IUMPRInhibit_P0D94_write_IRV: type=Boolean, init-value=0, variation-point={short-label=vpIUMPRInhibit_P0D94_write_IRV, sw-syscond=1}
          IUMPRInhibit_P0CD2_write_IRV: type=Boolean, init-value=0, variation-point={short-label=vpIUMPRInhibit_P0CD2_write_IRV, sw-syscond=1}
          IUMPR_DeviceCmdOn_LK_write_IRV: type=Boolean, init-value=0, variation-point={short-label=vpIUMPR_DeviceCmdOn_LK_write_IRV, sw-syscond=1}
          IUMPR_DeviceCmdOn_UL_write_IRV: type=Boolean, init-value=0, variation-point={short-label=vpIUMPR_DeviceCmdOn_UL_write_IRV, sw-syscond=1}
      5 x runnable:
        CDMR_ac_Init
          data-send-points:
            16 x access:
              OUT_VeCDMR_e_FaultSts_BattChrgPrtLckCktLo_Value: accessed-variable=VeCDMR_e_FaultSts_BattChrgPrtLckCktLo.Value
              OUT_VeCDMR_e_FaultSts_BattChrgPrtLckCkttHi_Value: accessed-variable=VeCDMR_e_FaultSts_BattChrgPrtLckCkttHi.Value
              OUT_VeCDMR_e_FaultSts_ChrgPortLckCtrlCktPerf_Value: accessed-variable=VeCDMR_e_FaultSts_ChrgPortLckCtrlCktPerf.Value
              OUT_VeCDMR_e_FaultSts_ChrgPortULCtrlCktPerf_Value: accessed-variable=VeCDMR_e_FaultSts_ChrgPortULCtrlCktPerf.Value
              OUT_VeCDMR_e_FaultSts_BatChrgModSwStk_Value: accessed-variable=VeCDMR_e_FaultSts_BatChrgModSwStk.Value
              OUT_VeCDMR_e_FaultSts_Module_Failure_BCIM_Value: accessed-variable=VeCDMR_e_FaultSts_Module_Failure_BCIM.Value
              OUT_VeCDMR_e_FaultSts_Module_Failure_CPIM_Value: accessed-variable=VeCDMR_e_FaultSts_Module_Failure_CPIM.Value
              OUT_VeCDMR_e_FaultSts_BatChaCouTemATooHig_Value: accessed-variable=VeCDMR_e_FaultSts_BatChaCouTemATooHig.Value
              OUT_VeCDMR_e_FaultSts_PwrOutletPanelMod1Perf_Value: accessed-variable=VeCDMR_e_FaultSts_PwrOutletPanelMod1Perf.Value
              OUT_VeCDMR_e_FaultSts_PwrOutletPanelMod2Perf_Value: accessed-variable=VeCDMR_e_FaultSts_PwrOutletPanelMod2Perf.Value
              OUT_VeCDMR_e_FaultSts_PwrOutletPanelMod1DigCommBus_Value: accessed-variable=VeCDMR_e_FaultSts_PwrOutletPanelMod1DigCommBus.Value
              OUT_VeCDMR_e_FaultSts_PwrOutletPanelMod2DigCommBus_Value: accessed-variable=VeCDMR_e_FaultSts_PwrOutletPanelMod2DigCommBus.Value
              OUT_VeCDMR_e_FaultSts_PwrOutletPanelMod1LmpCntrl_Value: accessed-variable=VeCDMR_e_FaultSts_PwrOutletPanelMod1LmpCntrl.Value
              OUT_VeCDMR_e_FaultSts_PwrOutletPanelMod2LmpCntrl_Value: accessed-variable=VeCDMR_e_FaultSts_PwrOutletPanelMod2LmpCntrl.Value
              OUT_VeCDMR_e_FaultSts_PwrOutletPanelMod1InACPwrCktPerf_Value: accessed-variable=VeCDMR_e_FaultSts_PwrOutletPanelMod1InACPwrCktPerf.Value
              OUT_VeCDMR_e_FaultSts_PwrOutletPanelMod2InACPwrCktPerf_Value: accessed-variable=VeCDMR_e_FaultSts_PwrOutletPanelMod2InACPwrCktPerf.Value
        CDMR_PwrOn
          data-receive-point-by-arguments:
            15 x access:
              IN_NeCDMR_Cnt_BCIMInternal_MFOP_Rx_NeCDMR_Cnt_BCIMInternal_MFOP: accessed-variable=NeCDMR_Cnt_BCIMInternal_MFOP_Rx.NeCDMR_Cnt_BCIMInternal_MFOP
              IN_NeCDMR_Cnt_CPIMInternal_MFOP_Rx_NeCDMR_Cnt_CPIMInternal_MFOP: accessed-variable=NeCDMR_Cnt_CPIMInternal_MFOP_Rx.NeCDMR_Cnt_CPIMInternal_MFOP
              IN_NeCDMR_Cnt_ChgPrtLckFailHMFOP_Rx_NeCDMR_Cnt_ChgPrtLckFailHMFOP: accessed-variable=NeCDMR_Cnt_ChgPrtLckFailHMFOP_Rx.NeCDMR_Cnt_ChgPrtLckFailHMFOP
              IN_NeCDMR_Cnt_ChgPrtLckFailLMFOP_Rx_NeCDMR_Cnt_ChgPrtLckFailLMFOP: accessed-variable=NeCDMR_Cnt_ChgPrtLckFailLMFOP_Rx.NeCDMR_Cnt_ChgPrtLckFailLMFOP
              IN_NeCDMR_Cnt_ChrgPortLock_MFOP_Rx_NeCDMR_Cnt_ChrgPortLock_MFOP: accessed-variable=NeCDMR_Cnt_ChrgPortLock_MFOP_Rx.NeCDMR_Cnt_ChrgPortLock_MFOP
              IN_NeCDMR_Cnt_ChrgPortUnlock_MFOP_Rx_NeCDMR_Cnt_ChrgPortUnlock_MFOP: accessed-variable=NeCDMR_Cnt_ChrgPortUnlock_MFOP_Rx.NeCDMR_Cnt_ChrgPortUnlock_MFOP
              IN_NeCDMR_Cnt_DTCShortName1_MFOP_Rx_NeCDMR_Cnt_DTCShortName1_MFOP: accessed-variable=NeCDMR_Cnt_DTCShortName1_MFOP_Rx.NeCDMR_Cnt_DTCShortName1_MFOP
              IN_NeCDMR_Cnt_DTCShortName6_MFOP_Rx_NeCDMR_Cnt_DTCShortName6_MFOP: accessed-variable=NeCDMR_Cnt_DTCShortName6_MFOP_Rx.NeCDMR_Cnt_DTCShortName6_MFOP
              IN_NeCDMR_Cnt_InletSensor_MFOP_Rx_NeCDMR_Cnt_InletSensor_MFOP: accessed-variable=NeCDMR_Cnt_InletSensor_MFOP_Rx.NeCDMR_Cnt_InletSensor_MFOP
              IN_NeCDMR_Cnt_PwrOutletPanelMod1InACPwrCktPerf_MFOP_Rx_NeCDMR_Cnt_PwrOutletPanelMod1InACPwrCktPerf_MFOP: accessed-variable=NeCDMR_Cnt_PwrOutletPanelMod1InACPwrCktPerf_MFOP_Rx.NeCDMR_Cnt_PwrOutletPanelMod1InACPwrCktPerf_MFOP
              IN_NeCDMR_Cnt_PwrOutletPanelMod1LmpCntrl_MFOP_Rx_NeCDMR_Cnt_PwrOutletPanelMod1LmpCntrl_MFOP: accessed-variable=NeCDMR_Cnt_PwrOutletPanelMod1LmpCntrl_MFOP_Rx.NeCDMR_Cnt_PwrOutletPanelMod1LmpCntrl_MFOP
              IN_NeCDMR_Cnt_PwrOutletPanelMod1Perf_MFOP_Rx_NeCDMR_Cnt_PwrOutletPanelMod1Perf_MFOP: accessed-variable=NeCDMR_Cnt_PwrOutletPanelMod1Perf_MFOP_Rx.NeCDMR_Cnt_PwrOutletPanelMod1Perf_MFOP
              IN_NeCDMR_Cnt_PwrOutletPanelMod2DigCommBus_MFOP_Rx_NeCDMR_Cnt_PwrOutletPanelMod2DigCommBus_MFOP: accessed-variable=NeCDMR_Cnt_PwrOutletPanelMod2DigCommBus_MFOP_Rx.NeCDMR_Cnt_PwrOutletPanelMod2DigCommBus_MFOP
              IN_NeCDMR_Cnt_PwrOutletPanelMod2InACPwrCktPerf_MFOP_Rx_NeCDMR_Cnt_PwrOutletPanelMod2InACPwrCktPerf_MFOP: accessed-variable=NeCDMR_Cnt_PwrOutletPanelMod2InACPwrCktPerf_MFOP_Rx.NeCDMR_Cnt_PwrOutletPanelMod2InACPwrCktPerf_MFOP
              IN_NeCDMR_Cnt_PwrOutletPanelMod2LmpCntrl_MFOP_Rx_NeCDMR_Cnt_PwrOutletPanelMod2LmpCntrl_MFOP: accessed-variable=NeCDMR_Cnt_PwrOutletPanelMod2LmpCntrl_MFOP_Rx.NeCDMR_Cnt_PwrOutletPanelMod2LmpCntrl_MFOP
          data-send-points:
            31 x access:
              OUT_VeCDMR_b_IUMPR_DeviceCmdOn_UL_Value: accessed-variable=VeCDMR_b_IUMPR_DeviceCmdOn_UL.Value
              OUT_VeCDMR_b_ChrgPortUL_FltDtct_Value: accessed-variable=VeCDMR_b_ChrgPortUL_FltDtct.Value
              OUT_VeCDMR_b_ChrgPortLK_FltDtct_Value: accessed-variable=VeCDMR_b_ChrgPortLK_FltDtct.Value
              OUT_VeCDMR_b_IUMPR_ChrgPortLock_Value: accessed-variable=VeCDMR_b_IUMPR_ChrgPortLock.Value
              OUT_VeCDMR_b_IUMPR_ChrgPortULock_Value: accessed-variable=VeCDMR_b_IUMPR_ChrgPortULock.Value
              OUT_VeCDMR_b_IUMPR_DeviceCmdOn_LK_Value: accessed-variable=VeCDMR_b_IUMPR_DeviceCmdOn_LK.Value
              OUT_VeCDMR_b_CPIM_ClrMismtch_Value: accessed-variable=VeCDMR_b_CPIM_ClrMismtch.Value
              OUT_VeCDMR_b_CPIM_Icon_Mismtch_Value: accessed-variable=VeCDMR_b_CPIM_Icon_Mismtch.Value
              OUT_VeCDMR_b_CPIM_LED_ShrtOrOpn_Value: accessed-variable=VeCDMR_b_CPIM_LED_ShrtOrOpn.Value
              OUT_VeCDMR_b_CPIM_HW_BusFlt_Value: accessed-variable=VeCDMR_b_CPIM_HW_BusFlt.Value
              OUT_VeCDMR_b_BCIM_ClrMismtch_Value: accessed-variable=VeCDMR_b_BCIM_ClrMismtch.Value
              OUT_VeCDMR_b_BCIM_LED_ShrtOrOpn_Value: accessed-variable=VeCDMR_b_BCIM_LED_ShrtOrOpn.Value
              OUT_VeCDMR_b_BCIM_HW_BusFlt_Value: accessed-variable=VeCDMR_b_BCIM_HW_BusFlt.Value
              OUT_VeCDMR_b_ChgPrtLckLowDTC_Value: accessed-variable=VeCDMR_b_ChgPrtLckLowDTC.Value
              OUT_VeCDMR_b_ChgPrtLckHiDTC_Value: accessed-variable=VeCDMR_b_ChgPrtLckHiDTC.Value
              OUT_VeCDMR_e_FaultSts_BattChrgPrtLckCktLo_Value: accessed-variable=VeCDMR_e_FaultSts_BattChrgPrtLckCktLo.Value
              OUT_VeCDMR_e_FaultSts_BattChrgPrtLckCkttHi_Value: accessed-variable=VeCDMR_e_FaultSts_BattChrgPrtLckCkttHi.Value
              OUT_VeCDMR_e_FaultSts_ChrgPortLckCtrlCktPerf_Value: accessed-variable=VeCDMR_e_FaultSts_ChrgPortLckCtrlCktPerf.Value
              OUT_VeCDMR_e_FaultSts_ChrgPortULCtrlCktPerf_Value: accessed-variable=VeCDMR_e_FaultSts_ChrgPortULCtrlCktPerf.Value
              OUT_VeCDMR_e_FaultSts_BatChrgModSwStk_Value: accessed-variable=VeCDMR_e_FaultSts_BatChrgModSwStk.Value
              OUT_VeCDMR_e_FaultSts_Module_Failure_BCIM_Value: accessed-variable=VeCDMR_e_FaultSts_Module_Failure_BCIM.Value
              OUT_VeCDMR_e_FaultSts_Module_Failure_CPIM_Value: accessed-variable=VeCDMR_e_FaultSts_Module_Failure_CPIM.Value
              OUT_VeCDMR_e_FaultSts_BatChaCouTemATooHig_Value: accessed-variable=VeCDMR_e_FaultSts_BatChaCouTemATooHig.Value
              OUT_VeCDMR_e_FaultSts_PwrOutletPanelMod1Perf_Value: accessed-variable=VeCDMR_e_FaultSts_PwrOutletPanelMod1Perf.Value
              OUT_VeCDMR_e_FaultSts_PwrOutletPanelMod2Perf_Value: accessed-variable=VeCDMR_e_FaultSts_PwrOutletPanelMod2Perf.Value
              OUT_VeCDMR_e_FaultSts_PwrOutletPanelMod1DigCommBus_Value: accessed-variable=VeCDMR_e_FaultSts_PwrOutletPanelMod1DigCommBus.Value
              OUT_VeCDMR_e_FaultSts_PwrOutletPanelMod2DigCommBus_Value: accessed-variable=VeCDMR_e_FaultSts_PwrOutletPanelMod2DigCommBus.Value
              OUT_VeCDMR_e_FaultSts_PwrOutletPanelMod1LmpCntrl_Value: accessed-variable=VeCDMR_e_FaultSts_PwrOutletPanelMod1LmpCntrl.Value
              OUT_VeCDMR_e_FaultSts_PwrOutletPanelMod2LmpCntrl_Value: accessed-variable=VeCDMR_e_FaultSts_PwrOutletPanelMod2LmpCntrl.Value
              OUT_VeCDMR_e_FaultSts_PwrOutletPanelMod1InACPwrCktPerf_Value: accessed-variable=VeCDMR_e_FaultSts_PwrOutletPanelMod1InACPwrCktPerf.Value
              OUT_VeCDMR_e_FaultSts_PwrOutletPanelMod2InACPwrCktPerf_Value: accessed-variable=VeCDMR_e_FaultSts_PwrOutletPanelMod2InACPwrCktPerf.Value
          written-local-variables:
            16 x access:
              WV_BCIMCommBusFaultStatus_write_IRV: accessed-variable=BCIMCommBusFaultStatus_write_IRV, variation-point={short-label=vpWV_BCIMCommBusFaultStatus_write_IRV, sw-syscond=1}
              WV_CPIMCommBusFaultStatus_write_IRV: accessed-variable=CPIMCommBusFaultStatus_write_IRV, variation-point={short-label=vpWV_CPIMCommBusFaultStatus_write_IRV, sw-syscond=1}
              WV_CPIMLostCommFaultStatus_write_IRV: accessed-variable=CPIMLostCommFaultStatus_write_IRV, variation-point={short-label=vpWV_CPIMLostCommFaultStatus_write_IRV, sw-syscond=1}
              WV_ChargingSystemSts_write_IRV: accessed-variable=ChargingSystemSts_write_IRV, variation-point={short-label=vpWV_ChargingSystemSts_write_IRV, sw-syscond=1}
              WV_ChgPrtLckHiDTC_write_IRV: accessed-variable=ChgPrtLckHiDTC_write_IRV, variation-point={short-label=vpWV_ChgPrtLckHiDTC_write_IRV, sw-syscond=1}
              WV_ChgPrtLckLowDTC_write_IRV: accessed-variable=ChgPrtLckLowDTC_write_IRV, variation-point={short-label=vpWV_ChgPrtLckLowDTC_write_IRV, sw-syscond=1}
              WV_ChrgPortLK_FltDtct_write_IRV: accessed-variable=ChrgPortLK_FltDtct_write_IRV, variation-point={short-label=vpWV_ChrgPortLK_FltDtct_write_IRV, sw-syscond=1}
              WV_ChrgPortUL_FltDtct_write_IRV: accessed-variable=ChrgPortUL_FltDtct_write_IRV, variation-point={short-label=vpWV_ChrgPortUL_FltDtct_write_IRV, sw-syscond=1}
              WV_DsblDiagFailSafe_write_IRV: accessed-variable=DsblDiagFailSafe_write_IRV, variation-point={short-label=vpWV_DsblDiagFailSafe_write_IRV, sw-syscond=1}
              WV_IUMPRInhibit_P0CD2_write_IRV: accessed-variable=IUMPRInhibit_P0CD2_write_IRV, variation-point={short-label=vpWV_IUMPRInhibit_P0CD2_write_IRV, sw-syscond=1}
              WV_IUMPRInhibit_P0D94_write_IRV: accessed-variable=IUMPRInhibit_P0D94_write_IRV, variation-point={short-label=vpWV_IUMPRInhibit_P0D94_write_IRV, sw-syscond=1}
              WV_IUMPR_DeviceCmdOn_LK_write_IRV: accessed-variable=IUMPR_DeviceCmdOn_LK_write_IRV, variation-point={short-label=vpWV_IUMPR_DeviceCmdOn_LK_write_IRV, sw-syscond=1}
              WV_IUMPR_DeviceCmdOn_UL_write_IRV: accessed-variable=IUMPR_DeviceCmdOn_UL_write_IRV, variation-point={short-label=vpWV_IUMPR_DeviceCmdOn_UL_write_IRV, sw-syscond=1}
              WV_IsDiagGlobalConditionsValid_write_IRV: accessed-variable=IsDiagGlobalConditionsValid_write_IRV, variation-point={short-label=vpWV_IsDiagGlobalConditionsValid_write_IRV, sw-syscond=1}
              WV_PluggedIn_write_IRV: accessed-variable=PluggedIn_write_IRV, variation-point={short-label=vpWV_PluggedIn_write_IRV, sw-syscond=1}
              WV_PostCodeClrDiagDsbl_write_IRV: accessed-variable=PostCodeClrDiagDsbl_write_IRV, variation-point={short-label=vpWV_PostCodeClrDiagDsbl_write_IRV, sw-syscond=1}
        CDMR_MedTED: variation-point={short-label=vpCDMR_MedTED, sw-syscond=1}
          data-receive-point-by-arguments:
            26 x access:
              IN_VeCANR_b_CBCLossComm_InKeyOff_VeCANR_b_CBCLossComm_InKeyOff: accessed-variable=VeCANR_b_CBCLossComm_InKeyOff.VeCANR_b_CBCLossComm_InKeyOff, variation-point={short-label=vpIN_VeCANR_b_CBCLossComm_InKeyOff_VeCANR_b_CBCLossComm_InKeyOff, sw-syscond=1}
              IN_VeCITR_b_ChrgPortLockSts_Value: accessed-variable=VeCITR_b_ChrgPortLockSts.Value, variation-point={short-label=vpIN_VeCITR_b_ChrgPortLockSts_Value, sw-syscond=1}
              IN_VeCITR_b_ChrgPortLock_StsB_FA_Value: accessed-variable=VeCITR_b_ChrgPortLock_StsB_FA.Value, variation-point={short-label=vpIN_VeCITR_b_ChrgPortLock_StsB_FA_Value, sw-syscond=1}
              IN_VeCITR_b_ChrgPortLock_StsC_Value: accessed-variable=VeCITR_b_ChrgPortLock_StsC.Value, variation-point={short-label=vpIN_VeCITR_b_ChrgPortLock_StsC_Value, sw-syscond=1}
              IN_VeCITR_b_ChrgPortLock_StsC_FA_Value: accessed-variable=VeCITR_b_ChrgPortLock_StsC_FA.Value, variation-point={short-label=vpIN_VeCITR_b_ChrgPortLock_StsC_FA_Value, sw-syscond=1}
              IN_VeCITR_b_HBridge_ChrgPortLck_Cal_Value: accessed-variable=VeCITR_b_HBridge_ChrgPortLck_Cal.Value, variation-point={short-label=vpIN_VeCITR_b_HBridge_ChrgPortLck_Cal_Value, sw-syscond=1}
              IN_VeCITR_b_PortLockBCM_Cmd_Value: accessed-variable=VeCITR_b_PortLockBCM_Cmd.Value, variation-point={short-label=vpIN_VeCITR_b_PortLockBCM_Cmd_Value, sw-syscond=1}
              IN_VeCITR_d_ChrgPortHbridgeFlt_Value: accessed-variable=VeCITR_d_ChrgPortHbridgeFlt.Value, variation-point={short-label=vpIN_VeCITR_d_ChrgPortHbridgeFlt_Value, sw-syscond=1}
              IN_VeCITR_e_CPIM_ChrgPortLock_FailSts_Value: accessed-variable=VeCITR_e_CPIM_ChrgPortLock_FailSts.Value, variation-point={short-label=vpIN_VeCITR_e_CPIM_ChrgPortLock_FailSts_Value, sw-syscond=1}
              IN_VeCITR_e_ChrgPortLock_StsB_Value: accessed-variable=VeCITR_e_ChrgPortLock_StsB.Value, variation-point={short-label=vpIN_VeCITR_e_ChrgPortLock_StsB_Value, sw-syscond=1}
              IN_VeDFIR_b_DsblDiagFailSafe_Value: accessed-variable=VeDFIR_b_DsblDiagFailSafe.Value, variation-point={short-label=vpIN_VeDFIR_b_DsblDiagFailSafe_Value, sw-syscond=1}
              IN_VeDFIR_b_IsDiagGlobalConditionsValid_Value: accessed-variable=VeDFIR_b_IsDiagGlobalConditionsValid.Value, variation-point={short-label=vpIN_VeDFIR_b_IsDiagGlobalConditionsValid_Value, sw-syscond=1}
              IN_VeDFIR_b_PostCodeClrDiagDsbl_Value: accessed-variable=VeDFIR_b_PostCodeClrDiagDsbl.Value, variation-point={short-label=vpIN_VeDFIR_b_PostCodeClrDiagDsbl_Value, sw-syscond=1}
              IN_VeDMAB_y_StatusByte_BattChrgPrtLckCktLo_Value: accessed-variable=VeDMAB_y_StatusByte_BattChrgPrtLckCktLo.Value, variation-point={short-label=vpIN_VeDMAB_y_StatusByte_BattChrgPrtLckCktLo_Value, sw-syscond=1}
              IN_VeDMAB_y_StatusByte_BattChrgPrtLckCkttHi_Value: accessed-variable=VeDMAB_y_StatusByte_BattChrgPrtLckCkttHi.Value, variation-point={short-label=vpIN_VeDMAB_y_StatusByte_BattChrgPrtLckCkttHi_Value, sw-syscond=1}
              IN_VeDMAB_y_StatusByte_ChrgPortLckCtrlCktPerf_Value: accessed-variable=VeDMAB_y_StatusByte_ChrgPortLckCtrlCktPerf.Value, variation-point={short-label=vpIN_VeDMAB_y_StatusByte_ChrgPortLckCtrlCktPerf_Value, sw-syscond=1}
              IN_VeDMAB_y_StatusByte_ChrgPortULCtrlCktPerf_Value: accessed-variable=VeDMAB_y_StatusByte_ChrgPortULCtrlCktPerf.Value, variation-point={short-label=vpIN_VeDMAB_y_StatusByte_ChrgPortULCtrlCktPerf_Value, sw-syscond=1}
              IN_VeDMAB_y_StatusByte_HiSpdCANCommBus_Value: accessed-variable=VeDMAB_y_StatusByte_HiSpdCANCommBus.Value, variation-point={short-label=vpIN_VeDMAB_y_StatusByte_HiSpdCANCommBus_Value, sw-syscond=1}
              IN_VeDMAB_y_StatusByte_LIN{1..3}_BusOff_Value: accessed-variable=VeDMAB_y_StatusByte_LIN{1..3}_BusOff.Value, variation-point={short-label=vpIN_VeDMAB_y_StatusByte_LIN{1..3}_BusOff_Value, sw-syscond=1}
              IN_VeDMAB_y_StatusByte_LostCommBCM_Value: accessed-variable=VeDMAB_y_StatusByte_LostCommBCM.Value, variation-point={short-label=vpIN_VeDMAB_y_StatusByte_LostCommBCM_Value, sw-syscond=1}
              IN_VeDMAB_y_StatusByte_LostCommCPIM_Value: accessed-variable=VeDMAB_y_StatusByte_LostCommCPIM.Value, variation-point={short-label=vpIN_VeDMAB_y_StatusByte_LostCommCPIM_Value, sw-syscond=1}
              IN_VeOBCR_b_PluggedIn_Value: accessed-variable=VeOBCR_b_PluggedIn.Value, variation-point={short-label=vpIN_VeOBCR_b_PluggedIn_Value, sw-syscond=1}
              IN_VeOBCR_e_ChargingSystemSts_Value: accessed-variable=VeOBCR_e_ChargingSystemSts.Value, variation-point={short-label=vpIN_VeOBCR_e_ChargingSystemSts_Value, sw-syscond=1}
              IN_VeOBCR_e_ChrgPort_Req_Value: accessed-variable=VeOBCR_e_ChrgPort_Req.Value, variation-point={short-label=vpIN_VeOBCR_e_ChrgPort_Req_Value, sw-syscond=1}
          data-send-points:
            4 x access:
              OUT_VeCDMR_e_FaultSts_BattChrgPrtLckCktLo_Value: accessed-variable=VeCDMR_e_FaultSts_BattChrgPrtLckCktLo.Value
              OUT_VeCDMR_e_FaultSts_BattChrgPrtLckCkttHi_Value: accessed-variable=VeCDMR_e_FaultSts_BattChrgPrtLckCkttHi.Value
              OUT_VeCDMR_e_FaultSts_ChrgPortLckCtrlCktPerf_Value: accessed-variable=VeCDMR_e_FaultSts_ChrgPortLckCtrlCktPerf.Value
              OUT_VeCDMR_e_FaultSts_ChrgPortULCtrlCktPerf_Value: accessed-variable=VeCDMR_e_FaultSts_ChrgPortULCtrlCktPerf.Value
          written-local-variables:
            16 x access:
              WV_BCIMCommBusFaultStatus_write_IRV: accessed-variable=BCIMCommBusFaultStatus_write_IRV, variation-point={short-label=vpWV_BCIMCommBusFaultStatus_write_IRV, sw-syscond=1}
              WV_CPIMCommBusFaultStatus_write_IRV: accessed-variable=CPIMCommBusFaultStatus_write_IRV, variation-point={short-label=vpWV_CPIMCommBusFaultStatus_write_IRV, sw-syscond=1}
              WV_CPIMLostCommFaultStatus_write_IRV: accessed-variable=CPIMLostCommFaultStatus_write_IRV, variation-point={short-label=vpWV_CPIMLostCommFaultStatus_write_IRV, sw-syscond=1}
              WV_ChargingSystemSts_write_IRV: accessed-variable=ChargingSystemSts_write_IRV, variation-point={short-label=vpWV_ChargingSystemSts_write_IRV, sw-syscond=1}
              WV_ChgPrtLckHiDTC_write_IRV: accessed-variable=ChgPrtLckHiDTC_write_IRV, variation-point={short-label=vpWV_ChgPrtLckHiDTC_write_IRV, sw-syscond=1}
              WV_ChgPrtLckLowDTC_write_IRV: accessed-variable=ChgPrtLckLowDTC_write_IRV, variation-point={short-label=vpWV_ChgPrtLckLowDTC_write_IRV, sw-syscond=1}
              WV_ChrgPortLK_FltDtct_write_IRV: accessed-variable=ChrgPortLK_FltDtct_write_IRV, variation-point={short-label=vpWV_ChrgPortLK_FltDtct_write_IRV, sw-syscond=1}
              WV_ChrgPortUL_FltDtct_write_IRV: accessed-variable=ChrgPortUL_FltDtct_write_IRV, variation-point={short-label=vpWV_ChrgPortUL_FltDtct_write_IRV, sw-syscond=1}
              WV_DsblDiagFailSafe_write_IRV: accessed-variable=DsblDiagFailSafe_write_IRV, variation-point={short-label=vpWV_DsblDiagFailSafe_write_IRV, sw-syscond=1}
              WV_IUMPRInhibit_P0CD2_write_IRV: accessed-variable=IUMPRInhibit_P0CD2_write_IRV, variation-point={short-label=vpWV_IUMPRInhibit_P0CD2_write_IRV, sw-syscond=1}
              WV_IUMPRInhibit_P0D94_write_IRV: accessed-variable=IUMPRInhibit_P0D94_write_IRV, variation-point={short-label=vpWV_IUMPRInhibit_P0D94_write_IRV, sw-syscond=1}
              WV_IUMPR_DeviceCmdOn_LK_write_IRV: accessed-variable=IUMPR_DeviceCmdOn_LK_write_IRV, variation-point={short-label=vpWV_IUMPR_DeviceCmdOn_LK_write_IRV, sw-syscond=1}
              WV_IUMPR_DeviceCmdOn_UL_write_IRV: accessed-variable=IUMPR_DeviceCmdOn_UL_write_IRV, variation-point={short-label=vpWV_IUMPR_DeviceCmdOn_UL_write_IRV, sw-syscond=1}
              WV_IsDiagGlobalConditionsValid_write_IRV: accessed-variable=IsDiagGlobalConditionsValid_write_IRV, variation-point={short-label=vpWV_IsDiagGlobalConditionsValid_write_IRV, sw-syscond=1}
              WV_PluggedIn_write_IRV: accessed-variable=PluggedIn_write_IRV, variation-point={short-label=vpWV_PluggedIn_write_IRV, sw-syscond=1}
              WV_PostCodeClrDiagDsbl_write_IRV: accessed-variable=PostCodeClrDiagDsbl_write_IRV, variation-point={short-label=vpWV_PostCodeClrDiagDsbl_write_IRV, sw-syscond=1}
        CDMR_MedTEH: variation-point={short-label=vpCDMR_MedTEH, sw-syscond=1}
          data-receive-point-by-arguments:
            103 x access:
              IN_VeAATR_b_SCP_InletTemp_FA_Value: accessed-variable=VeAATR_b_SCP_InletTemp_FA.Value, variation-point={short-label=vpIN_VeAATR_b_SCP_InletTemp_FA_Value, sw-syscond=1}
              IN_VeCITR_I_PP2CurrentDrawSens1_Value: accessed-variable=VeCITR_I_PP2CurrentDrawSens1.Value, variation-point={short-label=vpIN_VeCITR_I_PP2CurrentDrawSens1_Value, sw-syscond=1}
              IN_VeCITR_I_PPCurrentDrawSens1_Value: accessed-variable=VeCITR_I_PPCurrentDrawSens1.Value, variation-point={short-label=vpIN_VeCITR_I_PPCurrentDrawSens1_Value, sw-syscond=1}
              IN_VeCITR_b_BCIM_LINChkSumErr_Value: accessed-variable=VeCITR_b_BCIM_LINChkSumErr.Value, variation-point={short-label=vpIN_VeCITR_b_BCIM_LINChkSumErr_Value, sw-syscond=1}
              IN_VeCITR_b_BCIM_LINDataErr_Value: accessed-variable=VeCITR_b_BCIM_LINDataErr.Value, variation-point={short-label=vpIN_VeCITR_b_BCIM_LINDataErr_Value, sw-syscond=1}
              IN_VeCITR_b_BCIM_LINParityErr_Value: accessed-variable=VeCITR_b_BCIM_LINParityErr.Value, variation-point={short-label=vpIN_VeCITR_b_BCIM_LINParityErr_Value, sw-syscond=1}
              IN_VeCITR_b_BCIM_OverTemp_Value: accessed-variable=VeCITR_b_BCIM_OverTemp.Value, variation-point={short-label=vpIN_VeCITR_b_BCIM_OverTemp_Value, sw-syscond=1}
              IN_VeCITR_b_BCIM_UnderVolt_Value: accessed-variable=VeCITR_b_BCIM_UnderVolt.Value, variation-point={short-label=vpIN_VeCITR_b_BCIM_UnderVolt_Value, sw-syscond=1}
              IN_VeCITR_b_CPIM_BlueLED_Sts_Value: accessed-variable=VeCITR_b_CPIM_BlueLED_Sts.Value, variation-point={short-label=vpIN_VeCITR_b_CPIM_BlueLED_Sts_Value, sw-syscond=1}
              IN_VeCITR_b_CPIM_GreenLED_Sts_Value: accessed-variable=VeCITR_b_CPIM_GreenLED_Sts.Value, variation-point={short-label=vpIN_VeCITR_b_CPIM_GreenLED_Sts_Value, sw-syscond=1}
              IN_VeCITR_b_CPIM_Icon1_FailSts_Value: accessed-variable=VeCITR_b_CPIM_Icon1_FailSts.Value, variation-point={short-label=vpIN_VeCITR_b_CPIM_Icon1_FailSts_Value, sw-syscond=1}
              IN_VeCITR_b_CPIM_Icon2_FailSts_Value: accessed-variable=VeCITR_b_CPIM_Icon2_FailSts.Value, variation-point={short-label=vpIN_VeCITR_b_CPIM_Icon2_FailSts_Value, sw-syscond=1}
              IN_VeCITR_b_CPIM_LINChkSumErr_Value: accessed-variable=VeCITR_b_CPIM_LINChkSumErr.Value, variation-point={short-label=vpIN_VeCITR_b_CPIM_LINChkSumErr_Value, sw-syscond=1}
              IN_VeCITR_b_CPIM_LINDataErr_Value: accessed-variable=VeCITR_b_CPIM_LINDataErr.Value, variation-point={short-label=vpIN_VeCITR_b_CPIM_LINDataErr_Value, sw-syscond=1}
              IN_VeCITR_b_CPIM_LINParityErr_Value: accessed-variable=VeCITR_b_CPIM_LINParityErr.Value, variation-point={short-label=vpIN_VeCITR_b_CPIM_LINParityErr_Value, sw-syscond=1}
              IN_VeCITR_b_CPIM_OverTemp_Value: accessed-variable=VeCITR_b_CPIM_OverTemp.Value, variation-point={short-label=vpIN_VeCITR_b_CPIM_OverTemp_Value, sw-syscond=1}
              IN_VeCITR_b_CPIM_RedLED_Sts_Value: accessed-variable=VeCITR_b_CPIM_RedLED_Sts.Value, variation-point={short-label=vpIN_VeCITR_b_CPIM_RedLED_Sts_Value, sw-syscond=1}
              IN_VeCITR_b_CPIM_UnderVolt_Value: accessed-variable=VeCITR_b_CPIM_UnderVolt.Value, variation-point={short-label=vpIN_VeCITR_b_CPIM_UnderVolt_Value, sw-syscond=1}
              IN_VeCITR_b_ChrgPortButton_Sts_Value: accessed-variable=VeCITR_b_ChrgPortButton_Sts.Value, variation-point={short-label=vpIN_VeCITR_b_ChrgPortButton_Sts_Value, sw-syscond=1}
              IN_VeCITR_b_PP2ACPresentSens1_Value: accessed-variable=VeCITR_b_PP2ACPresentSens1.Value, variation-point={short-label=vpIN_VeCITR_b_PP2ACPresentSens1_Value, sw-syscond=1}
              IN_VeCITR_b_PP2ButtonSts_Value: accessed-variable=VeCITR_b_PP2ButtonSts.Value, variation-point={short-label=vpIN_VeCITR_b_PP2ButtonSts_Value, sw-syscond=1}
              IN_VeCITR_b_PPACPresentSens1_Value: accessed-variable=VeCITR_b_PPACPresentSens1.Value, variation-point={short-label=vpIN_VeCITR_b_PPACPresentSens1_Value, sw-syscond=1}
              IN_VeCITR_b_PPButtonSts_Value: accessed-variable=VeCITR_b_PPButtonSts.Value, variation-point={short-label=vpIN_VeCITR_b_PPButtonSts_Value, sw-syscond=1}
              IN_VeCITR_e_BCIM_Ind1_FailSts_Value: accessed-variable=VeCITR_e_BCIM_Ind1_FailSts.Value, variation-point={short-label=vpIN_VeCITR_e_BCIM_Ind1_FailSts_Value, sw-syscond=1}
              IN_VeCITR_e_BCIM_Ind1_Fdbk_Value: accessed-variable=VeCITR_e_BCIM_Ind1_Fdbk.Value, variation-point={short-label=vpIN_VeCITR_e_BCIM_Ind1_Fdbk_Value, sw-syscond=1}
              IN_VeCITR_e_BCIM_Ind2_FailSts_Value: accessed-variable=VeCITR_e_BCIM_Ind2_FailSts.Value, variation-point={short-label=vpIN_VeCITR_e_BCIM_Ind2_FailSts_Value, sw-syscond=1}
              IN_VeCITR_e_BCIM_Ind2_Fdbk_Value: accessed-variable=VeCITR_e_BCIM_Ind2_Fdbk.Value, variation-point={short-label=vpIN_VeCITR_e_BCIM_Ind2_Fdbk_Value, sw-syscond=1}
              IN_VeCITR_e_BCIM_Ind3_FailSts_Value: accessed-variable=VeCITR_e_BCIM_Ind3_FailSts.Value, variation-point={short-label=vpIN_VeCITR_e_BCIM_Ind3_FailSts_Value, sw-syscond=1}
              IN_VeCITR_e_BCIM_Ind3_Fdbk_Value: accessed-variable=VeCITR_e_BCIM_Ind3_Fdbk.Value, variation-point={short-label=vpIN_VeCITR_e_BCIM_Ind3_Fdbk_Value, sw-syscond=1}
              IN_VeCITR_e_BCIM_Ind4_FailSts_Value: accessed-variable=VeCITR_e_BCIM_Ind4_FailSts.Value, variation-point={short-label=vpIN_VeCITR_e_BCIM_Ind4_FailSts_Value, sw-syscond=1}
              IN_VeCITR_e_BCIM_Ind4_Fdbk_Value: accessed-variable=VeCITR_e_BCIM_Ind4_Fdbk.Value, variation-point={short-label=vpIN_VeCITR_e_BCIM_Ind4_Fdbk_Value, sw-syscond=1}
              IN_VeCITR_e_BCIM_Ind5_FailSts_Value: accessed-variable=VeCITR_e_BCIM_Ind5_FailSts.Value, variation-point={short-label=vpIN_VeCITR_e_BCIM_Ind5_FailSts_Value, sw-syscond=1}
              IN_VeCITR_e_BCIM_Ind5_Fdbk_Value: accessed-variable=VeCITR_e_BCIM_Ind5_Fdbk.Value, variation-point={short-label=vpIN_VeCITR_e_BCIM_Ind5_Fdbk_Value, sw-syscond=1}
              IN_VeCITR_e_BCIM_Ind_Color_Fdbk_Value: accessed-variable=VeCITR_e_BCIM_Ind_Color_Fdbk.Value, variation-point={short-label=vpIN_VeCITR_e_BCIM_Ind_Color_Fdbk_Value, sw-syscond=1}
              IN_VeCITR_e_CPIM_BlueLED_FailSts_Value: accessed-variable=VeCITR_e_CPIM_BlueLED_FailSts.Value, variation-point={short-label=vpIN_VeCITR_e_CPIM_BlueLED_FailSts_Value, sw-syscond=1}
              IN_VeCITR_e_CPIM_GreenLED_FailSts_Value: accessed-variable=VeCITR_e_CPIM_GreenLED_FailSts.Value, variation-point={short-label=vpIN_VeCITR_e_CPIM_GreenLED_FailSts_Value, sw-syscond=1}
              IN_VeCITR_e_CPIM_Icon1_Sts_Value: accessed-variable=VeCITR_e_CPIM_Icon1_Sts.Value, variation-point={short-label=vpIN_VeCITR_e_CPIM_Icon1_Sts_Value, sw-syscond=1}
              IN_VeCITR_e_CPIM_Icon2_Sts_Value: accessed-variable=VeCITR_e_CPIM_Icon2_Sts.Value, variation-point={short-label=vpIN_VeCITR_e_CPIM_Icon2_Sts_Value, sw-syscond=1}
              IN_VeCITR_e_CPIM_Ind1_FailSts_Value: accessed-variable=VeCITR_e_CPIM_Ind1_FailSts.Value, variation-point={short-label=vpIN_VeCITR_e_CPIM_Ind1_FailSts_Value, sw-syscond=1}
              IN_VeCITR_e_CPIM_Ind1_Fdbk_Value: accessed-variable=VeCITR_e_CPIM_Ind1_Fdbk.Value, variation-point={short-label=vpIN_VeCITR_e_CPIM_Ind1_Fdbk_Value, sw-syscond=1}
              IN_VeCITR_e_CPIM_Ind2_FailSts_Value: accessed-variable=VeCITR_e_CPIM_Ind2_FailSts.Value, variation-point={short-label=vpIN_VeCITR_e_CPIM_Ind2_FailSts_Value, sw-syscond=1}
              IN_VeCITR_e_CPIM_Ind2_Fdbk_Value: accessed-variable=VeCITR_e_CPIM_Ind2_Fdbk.Value, variation-point={short-label=vpIN_VeCITR_e_CPIM_Ind2_Fdbk_Value, sw-syscond=1}
              IN_VeCITR_e_CPIM_Ind3_FailSts_Value: accessed-variable=VeCITR_e_CPIM_Ind3_FailSts.Value, variation-point={short-label=vpIN_VeCITR_e_CPIM_Ind3_FailSts_Value, sw-syscond=1}
              IN_VeCITR_e_CPIM_Ind3_Fdbk_Value: accessed-variable=VeCITR_e_CPIM_Ind3_Fdbk.Value, variation-point={short-label=vpIN_VeCITR_e_CPIM_Ind3_Fdbk_Value, sw-syscond=1}
              IN_VeCITR_e_CPIM_Ind4_FailSts_Value: accessed-variable=VeCITR_e_CPIM_Ind4_FailSts.Value, variation-point={short-label=vpIN_VeCITR_e_CPIM_Ind4_FailSts_Value, sw-syscond=1}
              IN_VeCITR_e_CPIM_Ind4_Fdbk_Value: accessed-variable=VeCITR_e_CPIM_Ind4_Fdbk.Value, variation-point={short-label=vpIN_VeCITR_e_CPIM_Ind4_Fdbk_Value, sw-syscond=1}
              IN_VeCITR_e_CPIM_Ind5_FailSts_Value: accessed-variable=VeCITR_e_CPIM_Ind5_FailSts.Value, variation-point={short-label=vpIN_VeCITR_e_CPIM_Ind5_FailSts_Value, sw-syscond=1}
              IN_VeCITR_e_CPIM_Ind5_Fdbk_Value: accessed-variable=VeCITR_e_CPIM_Ind5_Fdbk.Value, variation-point={short-label=vpIN_VeCITR_e_CPIM_Ind5_Fdbk_Value, sw-syscond=1}
              IN_VeCITR_e_CPIM_Ind_Color_Fdbk_Value: accessed-variable=VeCITR_e_CPIM_Ind_Color_Fdbk.Value, variation-point={short-label=vpIN_VeCITR_e_CPIM_Ind_Color_Fdbk_Value, sw-syscond=1}
              IN_VeCITR_e_CPIM_RedLED_FailSts_Value: accessed-variable=VeCITR_e_CPIM_RedLED_FailSts.Value, variation-point={short-label=vpIN_VeCITR_e_CPIM_RedLED_FailSts_Value, sw-syscond=1}
              IN_VeCITR_e_PP2_LED_A_FailStatus_Value: accessed-variable=VeCITR_e_PP2_LED_A_FailStatus.Value, variation-point={short-label=vpIN_VeCITR_e_PP2_LED_A_FailStatus_Value, sw-syscond=1}
              IN_VeCITR_e_PP2_LED_A_Feedback_Value: accessed-variable=VeCITR_e_PP2_LED_A_Feedback.Value, variation-point={short-label=vpIN_VeCITR_e_PP2_LED_A_Feedback_Value, sw-syscond=1}
              IN_VeCITR_e_PP2_LED_B_FailStatus_Value: accessed-variable=VeCITR_e_PP2_LED_B_FailStatus.Value, variation-point={short-label=vpIN_VeCITR_e_PP2_LED_B_FailStatus_Value, sw-syscond=1}
              IN_VeCITR_e_PP2_LED_B_Feedback_Value: accessed-variable=VeCITR_e_PP2_LED_B_Feedback.Value, variation-point={short-label=vpIN_VeCITR_e_PP2_LED_B_Feedback_Value, sw-syscond=1}
              IN_VeCITR_e_PP_LED_A_FailStatus_Value: accessed-variable=VeCITR_e_PP_LED_A_FailStatus.Value, variation-point={short-label=vpIN_VeCITR_e_PP_LED_A_FailStatus_Value, sw-syscond=1}
              IN_VeCITR_e_PP_LED_A_Feedback_Value: accessed-variable=VeCITR_e_PP_LED_A_Feedback.Value, variation-point={short-label=vpIN_VeCITR_e_PP_LED_A_Feedback_Value, sw-syscond=1}
              IN_VeCITR_e_PP_LED_B_FailStatus_Value: accessed-variable=VeCITR_e_PP_LED_B_FailStatus.Value, variation-point={short-label=vpIN_VeCITR_e_PP_LED_B_FailStatus_Value, sw-syscond=1}
              IN_VeCITR_e_PP_LED_B_Feedback_Value: accessed-variable=VeCITR_e_PP_LED_B_Feedback.Value, variation-point={short-label=vpIN_VeCITR_e_PP_LED_B_Feedback_Value, sw-syscond=1}
              IN_VeDMAB_y_StatusByte_BatChaCouTemATooHig_Value: accessed-variable=VeDMAB_y_StatusByte_BatChaCouTemATooHig.Value, variation-point={short-label=vpIN_VeDMAB_y_StatusByte_BatChaCouTemATooHig_Value, sw-syscond=1}
              IN_VeDMAB_y_StatusByte_BatChrgModSwStk_Value: accessed-variable=VeDMAB_y_StatusByte_BatChrgModSwStk.Value, variation-point={short-label=vpIN_VeDMAB_y_StatusByte_BatChrgModSwStk_Value, sw-syscond=1}
              IN_VeDMAB_y_StatusByte_LostCommBCIM_Value: accessed-variable=VeDMAB_y_StatusByte_LostCommBCIM.Value, variation-point={short-label=vpIN_VeDMAB_y_StatusByte_LostCommBCIM_Value, sw-syscond=1}
              IN_VeDMAB_y_StatusByte_LostCommCPIM_Value: accessed-variable=VeDMAB_y_StatusByte_LostCommCPIM.Value, variation-point={short-label=vpIN_VeDMAB_y_StatusByte_LostCommCPIM_Value, sw-syscond=1}
              IN_VeDMAB_y_StatusByte_Module_Failure_BCIM_Value: accessed-variable=VeDMAB_y_StatusByte_Module_Failure_BCIM.Value, variation-point={short-label=vpIN_VeDMAB_y_StatusByte_Module_Failure_BCIM_Value, sw-syscond=1}
              IN_VeDMAB_y_StatusByte_Module_Failure_CPIM_Value: accessed-variable=VeDMAB_y_StatusByte_Module_Failure_CPIM.Value, variation-point={short-label=vpIN_VeDMAB_y_StatusByte_Module_Failure_CPIM_Value, sw-syscond=1}
              IN_VeDMAB_y_StatusByte_PwrOutletPanelMod1DigCommBus_Value: accessed-variable=VeDMAB_y_StatusByte_PwrOutletPanelMod1DigCommBus.Value, variation-point={short-label=vpIN_VeDMAB_y_StatusByte_PwrOutletPanelMod1DigCommBus_Value, sw-syscond=1}
              IN_VeDMAB_y_StatusByte_PwrOutletPanelMod1InACPwrCktPerf_Value: accessed-variable=VeDMAB_y_StatusByte_PwrOutletPanelMod1InACPwrCktPerf.Value, variation-point={short-label=vpIN_VeDMAB_y_StatusByte_PwrOutletPanelMod1InACPwrCktPerf_Value, sw-syscond=1}
              IN_VeDMAB_y_StatusByte_PwrOutletPanelMod1LmpCntrl_Value: accessed-variable=VeDMAB_y_StatusByte_PwrOutletPanelMod1LmpCntrl.Value, variation-point={short-label=vpIN_VeDMAB_y_StatusByte_PwrOutletPanelMod1LmpCntrl_Value, sw-syscond=1}
              IN_VeDMAB_y_StatusByte_PwrOutletPanelMod1Perf_Value: accessed-variable=VeDMAB_y_StatusByte_PwrOutletPanelMod1Perf.Value, variation-point={short-label=vpIN_VeDMAB_y_StatusByte_PwrOutletPanelMod1Perf_Value, sw-syscond=1}
              IN_VeDMAB_y_StatusByte_PwrOutletPanelMod2DigCommBus_Value: accessed-variable=VeDMAB_y_StatusByte_PwrOutletPanelMod2DigCommBus.Value, variation-point={short-label=vpIN_VeDMAB_y_StatusByte_PwrOutletPanelMod2DigCommBus_Value, sw-syscond=1}
              IN_VeDMAB_y_StatusByte_PwrOutletPanelMod2InACPwrCktPerf_Value: accessed-variable=VeDMAB_y_StatusByte_PwrOutletPanelMod2InACPwrCktPerf.Value, variation-point={short-label=vpIN_VeDMAB_y_StatusByte_PwrOutletPanelMod2InACPwrCktPerf_Value, sw-syscond=1}
              IN_VeDMAB_y_StatusByte_PwrOutletPanelMod2LmpCntrl_Value: accessed-variable=VeDMAB_y_StatusByte_PwrOutletPanelMod2LmpCntrl.Value, variation-point={short-label=vpIN_VeDMAB_y_StatusByte_PwrOutletPanelMod2LmpCntrl_Value, sw-syscond=1}
              IN_VeDMAB_y_StatusByte_PwrOutletPanelMod2Perf_Value: accessed-variable=VeDMAB_y_StatusByte_PwrOutletPanelMod2Perf.Value, variation-point={short-label=vpIN_VeDMAB_y_StatusByte_PwrOutletPanelMod2Perf_Value, sw-syscond=1}
              IN_VeIDCR_I_ACOutCurrent1_Value: accessed-variable=VeIDCR_I_ACOutCurrent1.Value, variation-point={short-label=vpIN_VeIDCR_I_ACOutCurrent1_Value, sw-syscond=1}
              IN_VeIDCR_U_ACOutVoltage1_Value: accessed-variable=VeIDCR_U_ACOutVoltage1.Value, variation-point={short-label=vpIN_VeIDCR_U_ACOutVoltage1_Value, sw-syscond=1}
              IN_VeOBCR_b_ChrgSysFault_Value: accessed-variable=VeOBCR_b_ChrgSysFault.Value, variation-point={short-label=vpIN_VeOBCR_b_ChrgSysFault_Value, sw-syscond=1}
              IN_VeOFCR_b_CPIM_BlueLED_Cmd_Value: accessed-variable=VeOFCR_b_CPIM_BlueLED_Cmd.Value, variation-point={short-label=vpIN_VeOFCR_b_CPIM_BlueLED_Cmd_Value, sw-syscond=1}
              IN_VeOFCR_b_CPIM_GreenLED_Cmd_Value: accessed-variable=VeOFCR_b_CPIM_GreenLED_Cmd.Value, variation-point={short-label=vpIN_VeOFCR_b_CPIM_GreenLED_Cmd_Value, sw-syscond=1}
              IN_VeOFCR_b_CPIM_RedLED_Cmd_Value: accessed-variable=VeOFCR_b_CPIM_RedLED_Cmd.Value, variation-point={short-label=vpIN_VeOFCR_b_CPIM_RedLED_Cmd_Value, sw-syscond=1}
              IN_VeOFCR_b_ChrgPortOT_StopChrg_Value: accessed-variable=VeOFCR_b_ChrgPortOT_StopChrg.Value, variation-point={short-label=vpIN_VeOFCR_b_ChrgPortOT_StopChrg_Value, sw-syscond=1}
              IN_VeOFCR_e_BCIM_ColorInd_Cmd_Value: accessed-variable=VeOFCR_e_BCIM_ColorInd_Cmd.Value, variation-point={short-label=vpIN_VeOFCR_e_BCIM_ColorInd_Cmd_Value, sw-syscond=1}
              IN_VeOFCR_e_BCIM_Ind{1..5}_Set_St_Value: accessed-variable=VeOFCR_e_BCIM_Ind{1..5}_Set_St.Value, variation-point={short-label=vpIN_VeOFCR_e_BCIM_Ind{1..5}_Set_St_Value, sw-syscond=1}
              IN_VeOFCR_e_CPIM_ColorInd_Cmd_Value: accessed-variable=VeOFCR_e_CPIM_ColorInd_Cmd.Value, variation-point={short-label=vpIN_VeOFCR_e_CPIM_ColorInd_Cmd_Value, sw-syscond=1}
              IN_VeOFCR_e_CPIM_Icon1_Cmd_Value: accessed-variable=VeOFCR_e_CPIM_Icon1_Cmd.Value, variation-point={short-label=vpIN_VeOFCR_e_CPIM_Icon1_Cmd_Value, sw-syscond=1}
              IN_VeOFCR_e_CPIM_Icon2_Cmd_Value: accessed-variable=VeOFCR_e_CPIM_Icon2_Cmd.Value, variation-point={short-label=vpIN_VeOFCR_e_CPIM_Icon2_Cmd_Value, sw-syscond=1}
              IN_VeOFCR_e_CPIM_Ind{1..5}_Cmd_Value: accessed-variable=VeOFCR_e_CPIM_Ind{1..5}_Cmd.Value, variation-point={short-label=vpIN_VeOFCR_e_CPIM_Ind{1..5}_Cmd_Value, sw-syscond=1}
              IN_VePMDB_b_PwrPanSwStatus_Value: accessed-variable=VePMDB_b_PwrPanSwStatus.Value, variation-point={short-label=vpIN_VePMDB_b_PwrPanSwStatus_Value, sw-syscond=1}
              IN_VePMTR_e_ThrmlDevEnbl_Value: accessed-variable=VePMTR_e_ThrmlDevEnbl.Value, variation-point={short-label=vpIN_VePMTR_e_ThrmlDevEnbl_Value, sw-syscond=1}
              IN_VeSCPR_b_ButtonActive_Door_Value: accessed-variable=VeSCPR_b_ButtonActive_Door.Value, variation-point={short-label=vpIN_VeSCPR_b_ButtonActive_Door_Value, sw-syscond=1}
              IN_VeVTLR_b_ACSw_Cmd_Value: accessed-variable=VeVTLR_b_ACSw_Cmd.Value, variation-point={short-label=vpIN_VeVTLR_b_ACSw_Cmd_Value, sw-syscond=1}
              IN_VeVTLR_e_FrunkSts_Value: accessed-variable=VeVTLR_e_FrunkSts.Value, variation-point={short-label=vpIN_VeVTLR_e_FrunkSts_Value, sw-syscond=1}
              IN_VeVTLR_e_PP1_LEDA_Cmd_Value: accessed-variable=VeVTLR_e_PP1_LEDA_Cmd.Value, variation-point={short-label=vpIN_VeVTLR_e_PP1_LEDA_Cmd_Value, sw-syscond=1}
              IN_VeVTLR_e_PP1_LEDB_Cmd_Value: accessed-variable=VeVTLR_e_PP1_LEDB_Cmd.Value, variation-point={short-label=vpIN_VeVTLR_e_PP1_LEDB_Cmd_Value, sw-syscond=1}
              IN_VeVTLR_e_PP2_LEDA_Cmd_Value: accessed-variable=VeVTLR_e_PP2_LEDA_Cmd.Value, variation-point={short-label=vpIN_VeVTLR_e_PP2_LEDA_Cmd_Value, sw-syscond=1}
              IN_VeVTLR_e_PP2_LEDB_Cmd_Value: accessed-variable=VeVTLR_e_PP2_LEDB_Cmd.Value, variation-point={short-label=vpIN_VeVTLR_e_PP2_LEDB_Cmd_Value, sw-syscond=1}
              IN_VeVTLR_e_TrunkSts_Value: accessed-variable=VeVTLR_e_TrunkSts.Value, variation-point={short-label=vpIN_VeVTLR_e_TrunkSts_Value, sw-syscond=1}
          data-send-points:
            27 x access:
              OUT_VeCDMR_b_CPIM_ClrMismtch_Value: accessed-variable=VeCDMR_b_CPIM_ClrMismtch.Value
              OUT_VeCDMR_b_CPIM_Icon_Mismtch_Value: accessed-variable=VeCDMR_b_CPIM_Icon_Mismtch.Value
              OUT_VeCDMR_b_CPIM_LED_ShrtOrOpn_Value: accessed-variable=VeCDMR_b_CPIM_LED_ShrtOrOpn.Value
              OUT_VeCDMR_b_CPIM_HW_BusFlt_Value: accessed-variable=VeCDMR_b_CPIM_HW_BusFlt.Value
              OUT_VeCDMR_b_BCIM_ClrMismtch_Value: accessed-variable=VeCDMR_b_BCIM_ClrMismtch.Value
              OUT_VeCDMR_b_BCIM_LED_ShrtOrOpn_Value: accessed-variable=VeCDMR_b_BCIM_LED_ShrtOrOpn.Value
              OUT_VeCDMR_b_BCIM_HW_BusFlt_Value: accessed-variable=VeCDMR_b_BCIM_HW_BusFlt.Value
              OUT_VeCDMR_b_IUMPR_DeviceCmdOn_UL_Value: accessed-variable=VeCDMR_b_IUMPR_DeviceCmdOn_UL.Value
              OUT_VeCDMR_b_ChrgPortUL_FltDtct_Value: accessed-variable=VeCDMR_b_ChrgPortUL_FltDtct.Value
              OUT_VeCDMR_b_ChrgPortLK_FltDtct_Value: accessed-variable=VeCDMR_b_ChrgPortLK_FltDtct.Value
              OUT_VeCDMR_b_IUMPR_ChrgPortLock_Value: accessed-variable=VeCDMR_b_IUMPR_ChrgPortLock.Value
              OUT_VeCDMR_b_IUMPR_ChrgPortULock_Value: accessed-variable=VeCDMR_b_IUMPR_ChrgPortULock.Value
              OUT_VeCDMR_b_IUMPR_DeviceCmdOn_LK_Value: accessed-variable=VeCDMR_b_IUMPR_DeviceCmdOn_LK.Value
              OUT_VeCDMR_b_ChgPrtLckLowDTC_Value: accessed-variable=VeCDMR_b_ChgPrtLckLowDTC.Value
              OUT_VeCDMR_b_ChgPrtLckHiDTC_Value: accessed-variable=VeCDMR_b_ChgPrtLckHiDTC.Value
              OUT_VeCDMR_e_FaultSts_BatChrgModSwStk_Value: accessed-variable=VeCDMR_e_FaultSts_BatChrgModSwStk.Value
              OUT_VeCDMR_e_FaultSts_Module_Failure_BCIM_Value: accessed-variable=VeCDMR_e_FaultSts_Module_Failure_BCIM.Value
              OUT_VeCDMR_e_FaultSts_Module_Failure_CPIM_Value: accessed-variable=VeCDMR_e_FaultSts_Module_Failure_CPIM.Value
              OUT_VeCDMR_e_FaultSts_BatChaCouTemATooHig_Value: accessed-variable=VeCDMR_e_FaultSts_BatChaCouTemATooHig.Value
              OUT_VeCDMR_e_FaultSts_PwrOutletPanelMod1Perf_Value: accessed-variable=VeCDMR_e_FaultSts_PwrOutletPanelMod1Perf.Value
              OUT_VeCDMR_e_FaultSts_PwrOutletPanelMod1DigCommBus_Value: accessed-variable=VeCDMR_e_FaultSts_PwrOutletPanelMod1DigCommBus.Value
              OUT_VeCDMR_e_FaultSts_PwrOutletPanelMod1LmpCntrl_Value: accessed-variable=VeCDMR_e_FaultSts_PwrOutletPanelMod1LmpCntrl.Value
              OUT_VeCDMR_e_FaultSts_PwrOutletPanelMod1InACPwrCktPerf_Value: accessed-variable=VeCDMR_e_FaultSts_PwrOutletPanelMod1InACPwrCktPerf.Value
              OUT_VeCDMR_e_FaultSts_PwrOutletPanelMod2Perf_Value: accessed-variable=VeCDMR_e_FaultSts_PwrOutletPanelMod2Perf.Value
              OUT_VeCDMR_e_FaultSts_PwrOutletPanelMod2DigCommBus_Value: accessed-variable=VeCDMR_e_FaultSts_PwrOutletPanelMod2DigCommBus.Value
              OUT_VeCDMR_e_FaultSts_PwrOutletPanelMod2LmpCntrl_Value: accessed-variable=VeCDMR_e_FaultSts_PwrOutletPanelMod2LmpCntrl.Value
              OUT_VeCDMR_e_FaultSts_PwrOutletPanelMod2InACPwrCktPerf_Value: accessed-variable=VeCDMR_e_FaultSts_PwrOutletPanelMod2InACPwrCktPerf.Value
          read-local-variables:
            16 x access:
              RV_BCIMCommBusFaultStatus_write_IRV: accessed-variable=BCIMCommBusFaultStatus_write_IRV, variation-point={short-label=vpRV_BCIMCommBusFaultStatus_write_IRV, sw-syscond=1}
              RV_CPIMCommBusFaultStatus_write_IRV: accessed-variable=CPIMCommBusFaultStatus_write_IRV, variation-point={short-label=vpRV_CPIMCommBusFaultStatus_write_IRV, sw-syscond=1}
              RV_CPIMLostCommFaultStatus_write_IRV: accessed-variable=CPIMLostCommFaultStatus_write_IRV, variation-point={short-label=vpRV_CPIMLostCommFaultStatus_write_IRV, sw-syscond=1}
              RV_ChargingSystemSts_write_IRV: accessed-variable=ChargingSystemSts_write_IRV, variation-point={short-label=vpRV_ChargingSystemSts_write_IRV, sw-syscond=1}
              RV_ChgPrtLckHiDTC_write_IRV: accessed-variable=ChgPrtLckHiDTC_write_IRV, variation-point={short-label=vpRV_ChgPrtLckHiDTC_write_IRV, sw-syscond=1}
              RV_ChgPrtLckLowDTC_write_IRV: accessed-variable=ChgPrtLckLowDTC_write_IRV, variation-point={short-label=vpRV_ChgPrtLckLowDTC_write_IRV, sw-syscond=1}
              RV_ChrgPortLK_FltDtct_write_IRV: accessed-variable=ChrgPortLK_FltDtct_write_IRV, variation-point={short-label=vpRV_ChrgPortLK_FltDtct_write_IRV, sw-syscond=1}
              RV_ChrgPortUL_FltDtct_write_IRV: accessed-variable=ChrgPortUL_FltDtct_write_IRV, variation-point={short-label=vpRV_ChrgPortUL_FltDtct_write_IRV, sw-syscond=1}
              RV_DsblDiagFailSafe_write_IRV: accessed-variable=DsblDiagFailSafe_write_IRV, variation-point={short-label=vpRV_DsblDiagFailSafe_write_IRV, sw-syscond=1}
              RV_IUMPRInhibit_P0CD2_write_IRV: accessed-variable=IUMPRInhibit_P0CD2_write_IRV, variation-point={short-label=vpRV_IUMPRInhibit_P0CD2_write_IRV, sw-syscond=1}
              RV_IUMPRInhibit_P0D94_write_IRV: accessed-variable=IUMPRInhibit_P0D94_write_IRV, variation-point={short-label=vpRV_IUMPRInhibit_P0D94_write_IRV, sw-syscond=1}
              RV_IUMPR_DeviceCmdOn_LK_write_IRV: accessed-variable=IUMPR_DeviceCmdOn_LK_write_IRV, variation-point={short-label=vpRV_IUMPR_DeviceCmdOn_LK_write_IRV, sw-syscond=1}
              RV_IUMPR_DeviceCmdOn_UL_write_IRV: accessed-variable=IUMPR_DeviceCmdOn_UL_write_IRV, variation-point={short-label=vpRV_IUMPR_DeviceCmdOn_UL_write_IRV, sw-syscond=1}
              RV_IsDiagGlobalConditionsValid_write_IRV: accessed-variable=IsDiagGlobalConditionsValid_write_IRV, variation-point={short-label=vpRV_IsDiagGlobalConditionsValid_write_IRV, sw-syscond=1}
              RV_PluggedIn_write_IRV: accessed-variable=PluggedIn_write_IRV, variation-point={short-label=vpRV_PluggedIn_write_IRV, sw-syscond=1}
              RV_PostCodeClrDiagDsbl_write_IRV: accessed-variable=PostCodeClrDiagDsbl_write_IRV, variation-point={short-label=vpRV_PostCodeClrDiagDsbl_write_IRV, sw-syscond=1}
        CDMR_PwrOff
          data-send-points:
            7 x access:
              OUT_NeCDMR_Cnt_BCIMInternal_MFOP_NeCDMR_Cnt_BCIMInternal_MFOP: accessed-variable=NeCDMR_Cnt_BCIMInternal_MFOP.NeCDMR_Cnt_BCIMInternal_MFOP
              OUT_NeCDMR_Cnt_CPIMInternal_MFOP_NeCDMR_Cnt_CPIMInternal_MFOP: accessed-variable=NeCDMR_Cnt_CPIMInternal_MFOP.NeCDMR_Cnt_CPIMInternal_MFOP
              OUT_NeCDMR_Cnt_ChgPrtLckFailHMFOP_NeCDMR_Cnt_ChgPrtLckFailHMFOP: accessed-variable=NeCDMR_Cnt_ChgPrtLckFailHMFOP.NeCDMR_Cnt_ChgPrtLckFailHMFOP
              OUT_NeCDMR_Cnt_ChgPrtLckFailLMFOP_NeCDMR_Cnt_ChgPrtLckFailLMFOP: accessed-variable=NeCDMR_Cnt_ChgPrtLckFailLMFOP.NeCDMR_Cnt_ChgPrtLckFailLMFOP
              OUT_NeCDMR_Cnt_ChrgPortLock_MFOP_NeCDMR_Cnt_ChrgPortLock_MFOP: accessed-variable=NeCDMR_Cnt_ChrgPortLock_MFOP.NeCDMR_Cnt_ChrgPortLock_MFOP
              OUT_NeCDMR_Cnt_ChrgPortUnlock_MFOP_NeCDMR_Cnt_ChrgPortUnlock_MFOP: accessed-variable=NeCDMR_Cnt_ChrgPortUnlock_MFOP.NeCDMR_Cnt_ChrgPortUnlock_MFOP
              OUT_NeCDMR_Cnt_InletSensor_MFOP_NeCDMR_Cnt_InletSensor_MFOP: accessed-variable=NeCDMR_Cnt_InletSensor_MFOP.NeCDMR_Cnt_InletSensor_MFOP
      4 x variation point proxy, all with category=CONDITION, condition-access=1:
        Variant_CDMR_{1..4}
